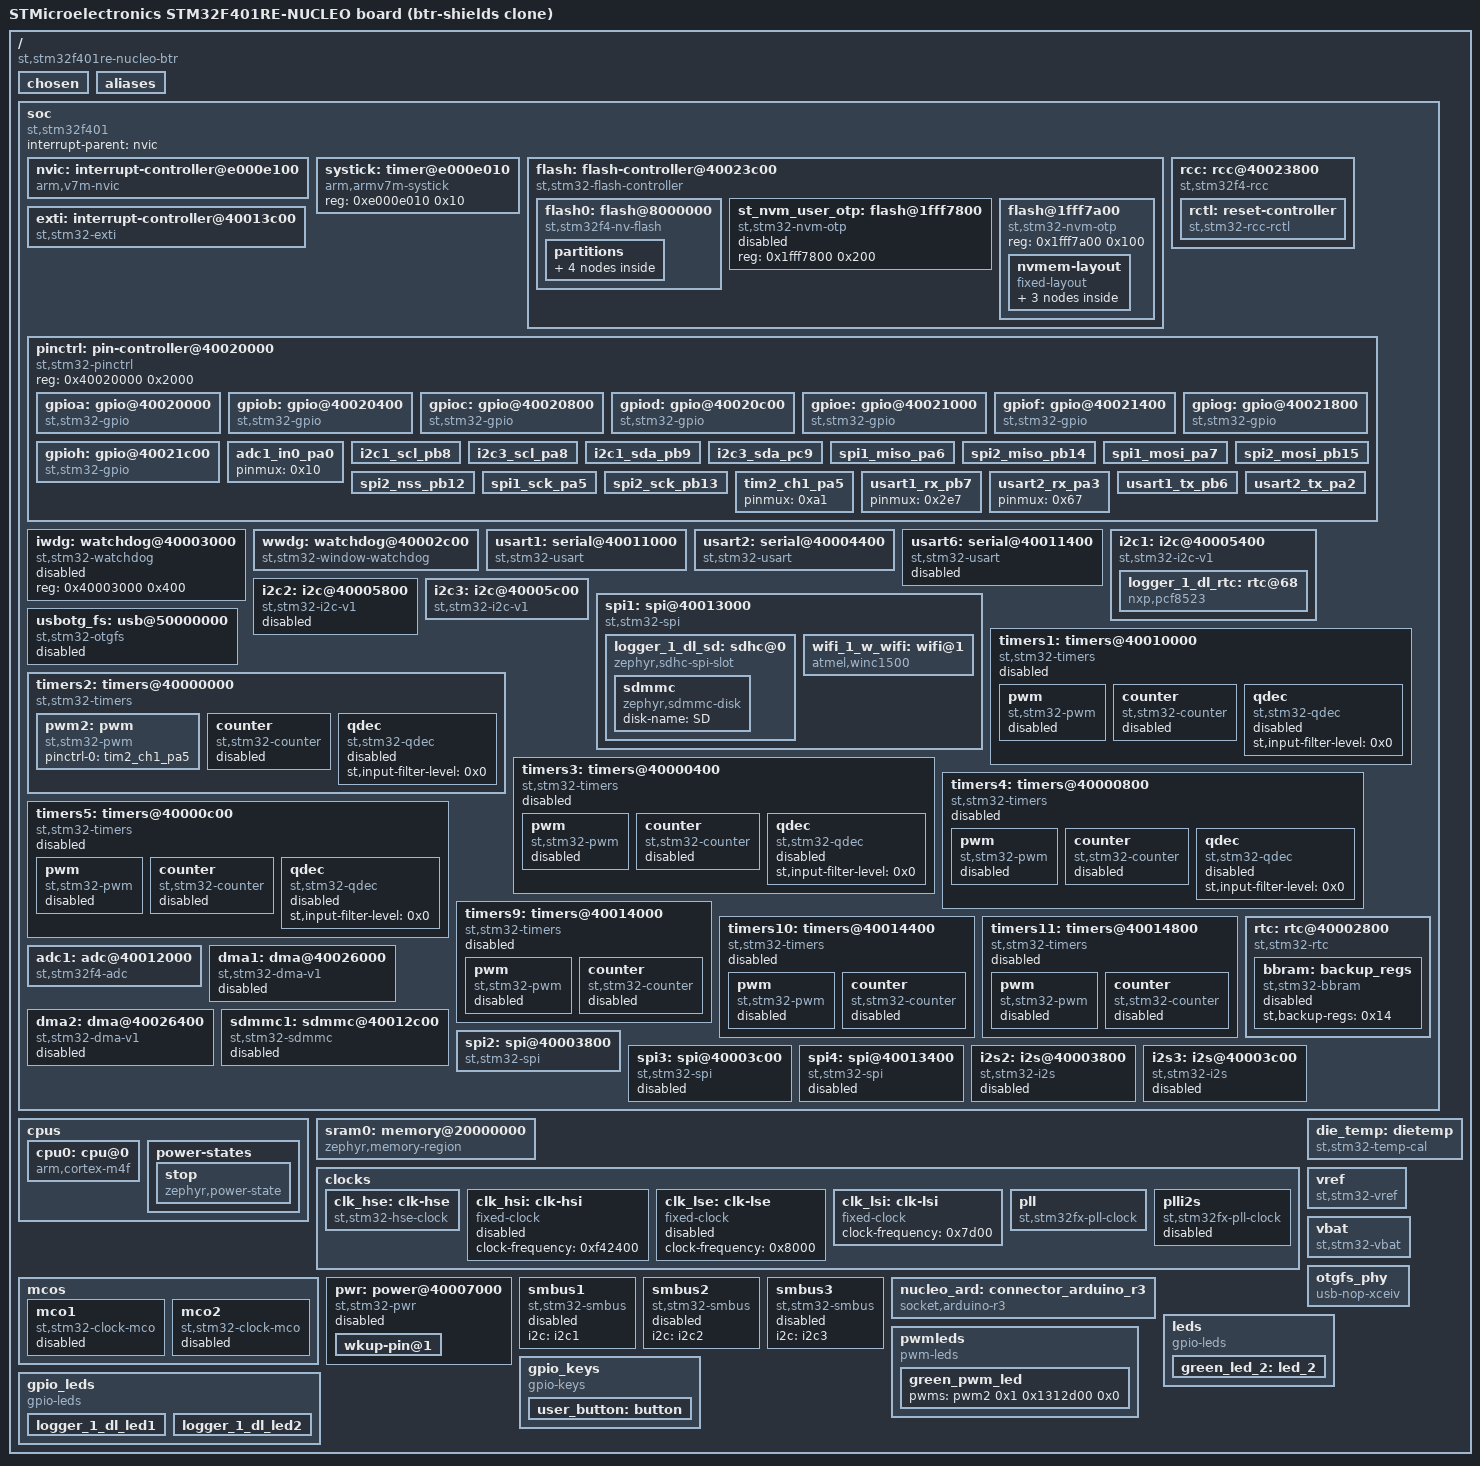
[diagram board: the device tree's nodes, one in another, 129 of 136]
/dts-v1/;

/* node '/' defined in zephyr-rigs/dts/common/skeleton.dtsi:9 */
/ {
	#address-cells = < 0x1 >;                                                  /* in zephyr-rigs/dts/common/skeleton.dtsi:10 */
	#size-cells = < 0x1 >;                                                     /* in zephyr-rigs/dts/common/skeleton.dtsi:11 */
	model = "STMicroelectronics STM32F401RE-NUCLEO board (btr-shields clone)"; /* in btr-shields/boards/st/nucleo_f401re_btr/nucleo_f401re_btr.dts:15 */
	compatible = "st,stm32f401re-nucleo-btr";                                  /* in btr-shields/boards/st/nucleo_f401re_btr/nucleo_f401re_btr.dts:16 */

	/* node '/chosen' defined in zephyr-rigs/dts/common/skeleton.dtsi:13 */
	chosen {
		zephyr,flash-controller = &flash;         /* in zephyr-rigs/dts/arm/st/f4/stm32f4.dtsi:26 */
		zephyr,system-timer-companion = &rtc;     /* in zephyr-rigs/dts/arm/st/f4/stm32f4.dtsi:27 */
		zephyr,console = &usart2;                 /* in btr-shields/boards/st/nucleo_f401re_btr/nucleo_f401re_btr.dts:19 */
		zephyr,shell-uart = &usart2;              /* in btr-shields/boards/st/nucleo_f401re_btr/nucleo_f401re_btr.dts:20 */
		zephyr,sram = &sram0;                     /* in btr-shields/boards/st/nucleo_f401re_btr/nucleo_f401re_btr.dts:21 */
		zephyr,flash = &flash0;                   /* in btr-shields/boards/st/nucleo_f401re_btr/nucleo_f401re_btr.dts:22 */
		zephyr,code-partition = &slot0_partition; /* in btr-shields/boards/st/nucleo_f401re_btr/nucleo_f401re_btr.dts:23 */
	};

	/* node '/aliases' defined in zephyr-rigs/dts/common/skeleton.dtsi:15 */
	aliases {
		led0 = &green_led_2;       /* in btr-shields/boards/st/nucleo_f401re_btr/nucleo_f401re_btr.dts:54 */
		sw0 = &user_button;        /* in btr-shields/boards/st/nucleo_f401re_btr/nucleo_f401re_btr.dts:55 */
		pwm-led0 = &green_pwm_led; /* in btr-shields/boards/st/nucleo_f401re_btr/nucleo_f401re_btr.dts:56 */
		watchdog0 = &wwdg;         /* in btr-shields/boards/st/nucleo_f401re_btr/nucleo_f401re_btr.dts:57 */
		die-temp0 = &die_temp;     /* in btr-shields/boards/st/nucleo_f401re_btr/nucleo_f401re_btr.dts:58 */
		rtc = &rtc;                /* in btr-shields/boards/st/nucleo_f401re_btr/nucleo_f401re_btr.dts:59 */
		volt-sensor0 = &vref;      /* in btr-shields/boards/st/nucleo_f401re_btr/nucleo_f401re_btr.dts:60 */
		volt-sensor1 = &vbat;      /* in btr-shields/boards/st/nucleo_f401re_btr/nucleo_f401re_btr.dts:61 */
	};

	/* node '/soc' defined in zephyr-rigs/dts/arm/armv7-m.dtsi:6 */
	soc {
		#address-cells = < 0x1 >;     /* in zephyr-rigs/dts/arm/armv7-m.dtsi:7 */
		#size-cells = < 0x1 >;        /* in zephyr-rigs/dts/arm/armv7-m.dtsi:8 */
		interrupt-parent = < &nvic >; /* in zephyr-rigs/dts/arm/armv7-m.dtsi:10 */
		ranges;                       /* in zephyr-rigs/dts/arm/armv7-m.dtsi:11 */
		compatible = "st,stm32f401",
		             "st,stm32f4",
		             "simple-bus";    /* in zephyr-rigs/dts/arm/st/f4/stm32f401.dtsi:19 */

		/* node '/soc/interrupt-controller@e000e100' defined in zephyr-rigs/dts/arm/armv7-m.dtsi:13 */
		nvic: interrupt-controller@e000e100 {
			#address-cells = < 0x1 >;            /* in zephyr-rigs/dts/arm/armv7-m.dtsi:14 */
			compatible = "arm,v7m-nvic";         /* in zephyr-rigs/dts/arm/armv7-m.dtsi:15 */
			reg = < 0xe000e100 0xc00 >;          /* in zephyr-rigs/dts/arm/armv7-m.dtsi:16 */
			interrupt-controller;                /* in zephyr-rigs/dts/arm/armv7-m.dtsi:17 */
			#interrupt-cells = < 0x2 >;          /* in zephyr-rigs/dts/arm/armv7-m.dtsi:18 */
			arm,num-irq-priority-bits = < 0x4 >; /* in zephyr-rigs/dts/arm/st/f4/stm32f4.dtsi:729 */
			phandle = < 0x1 >;                   /* in zephyr-rigs/dts/arm/armv7-m.dtsi:10 */
		};

		/* node '/soc/timer@e000e010' defined in zephyr-rigs/dts/arm/armv7-m.dtsi:21 */
		systick: timer@e000e010 {
			compatible = "arm,armv7m-systick"; /* in zephyr-rigs/dts/arm/armv7-m.dtsi:22 */
			reg = < 0xe000e010 0x10 >;         /* in zephyr-rigs/dts/arm/armv7-m.dtsi:23 */
		};

		/* node '/soc/flash-controller@40023c00' defined in zephyr-rigs/dts/arm/st/f4/stm32f4.dtsi:112 */
		flash: flash-controller@40023c00 {
			compatible = "st,stm32-flash-controller",
			             "st,stm32f4-flash-controller"; /* in zephyr-rigs/dts/arm/st/f4/stm32f4.dtsi:113 */
			reg = < 0x40023c00 0x400 >;                 /* in zephyr-rigs/dts/arm/st/f4/stm32f4.dtsi:114 */
			interrupts = < 0x4 0x0 >;                   /* in zephyr-rigs/dts/arm/st/f4/stm32f4.dtsi:115 */
			#address-cells = < 0x1 >;                   /* in zephyr-rigs/dts/arm/st/f4/stm32f4.dtsi:117 */
			#size-cells = < 0x1 >;                      /* in zephyr-rigs/dts/arm/st/f4/stm32f4.dtsi:118 */
			ranges;                                     /* in zephyr-rigs/dts/arm/st/f4/stm32f4.dtsi:119 */

			/* node '/soc/flash-controller@40023c00/flash@8000000' defined in zephyr-rigs/dts/arm/st/f4/stm32f4.dtsi:121 */
			flash0: flash@8000000 {
				compatible = "st,stm32f4-nv-flash",
				             "st,stm32-nv-flash",
				             "soc-nv-flash";        /* in zephyr-rigs/dts/arm/st/f4/stm32f4.dtsi:122 */
				#address-cells = < 0x1 >;           /* in zephyr-rigs/dts/arm/st/f4/stm32f4.dtsi:124 */
				#size-cells = < 0x1 >;              /* in zephyr-rigs/dts/arm/st/f4/stm32f4.dtsi:125 */
				write-block-size = < 0x1 >;         /* in zephyr-rigs/dts/arm/st/f4/stm32f4.dtsi:126 */
				max-erase-time = < 0xfa0 >;         /* in zephyr-rigs/dts/arm/st/f4/stm32f4.dtsi:128 */
				reg = < 0x8000000 0x80000 >;        /* in zephyr-rigs/dts/arm/st/f4/stm32f401Xe.dtsi:17 */
				ranges = < 0x0 0x8000000 0x80000 >; /* in zephyr-rigs/dts/arm/st/f4/stm32f401Xe.dtsi:18 */

				/* node '/soc/flash-controller@40023c00/flash@8000000/partitions' defined in btr-shields/boards/st/nucleo_f401re_btr/nucleo_f401re_btr.dts:139 */
				partitions {
					#address-cells = < 0x1 >; /* in btr-shields/boards/st/nucleo_f401re_btr/nucleo_f401re_btr.dts:140 */
					#size-cells = < 0x1 >;    /* in btr-shields/boards/st/nucleo_f401re_btr/nucleo_f401re_btr.dts:141 */
					ranges;                   /* in btr-shields/boards/st/nucleo_f401re_btr/nucleo_f401re_btr.dts:142 */

					/* node '/soc/flash-controller@40023c00/flash@8000000/partitions/partition@0' defined in btr-shields/boards/st/nucleo_f401re_btr/nucleo_f401re_btr.dts:144 */
					boot_partition: partition@0 {
						compatible = "zephyr,mapped-partition"; /* in btr-shields/boards/st/nucleo_f401re_btr/nucleo_f401re_btr.dts:145 */
						label = "mcuboot";                      /* in btr-shields/boards/st/nucleo_f401re_btr/nucleo_f401re_btr.dts:146 */
						reg = < 0x0 0x10000 >;                  /* in btr-shields/boards/st/nucleo_f401re_btr/nucleo_f401re_btr.dts:147 */
						read-only;                              /* in btr-shields/boards/st/nucleo_f401re_btr/nucleo_f401re_btr.dts:148 */
					};

					/* node '/soc/flash-controller@40023c00/flash@8000000/partitions/partition@20000' defined in btr-shields/boards/st/nucleo_f401re_btr/nucleo_f401re_btr.dts:156 */
					slot0_partition: partition@20000 {
						compatible = "zephyr,mapped-partition"; /* in btr-shields/boards/st/nucleo_f401re_btr/nucleo_f401re_btr.dts:157 */
						label = "image-0";                      /* in btr-shields/boards/st/nucleo_f401re_btr/nucleo_f401re_btr.dts:158 */
						reg = < 0x20000 0x20000 >;              /* in btr-shields/boards/st/nucleo_f401re_btr/nucleo_f401re_btr.dts:159 */
					};

					/* node '/soc/flash-controller@40023c00/flash@8000000/partitions/partition@40000' defined in btr-shields/boards/st/nucleo_f401re_btr/nucleo_f401re_btr.dts:162 */
					slot1_partition: partition@40000 {
						compatible = "zephyr,mapped-partition"; /* in btr-shields/boards/st/nucleo_f401re_btr/nucleo_f401re_btr.dts:163 */
						label = "image-1";                      /* in btr-shields/boards/st/nucleo_f401re_btr/nucleo_f401re_btr.dts:164 */
						reg = < 0x40000 0x20000 >;              /* in btr-shields/boards/st/nucleo_f401re_btr/nucleo_f401re_btr.dts:165 */
					};

					/* node '/soc/flash-controller@40023c00/flash@8000000/partitions/partition@60000' defined in btr-shields/boards/st/nucleo_f401re_btr/nucleo_f401re_btr.dts:168 */
					scratch_partition: partition@60000 {
						compatible = "zephyr,mapped-partition"; /* in btr-shields/boards/st/nucleo_f401re_btr/nucleo_f401re_btr.dts:169 */
						label = "image-scratch";                /* in btr-shields/boards/st/nucleo_f401re_btr/nucleo_f401re_btr.dts:170 */
						reg = < 0x60000 0x20000 >;              /* in btr-shields/boards/st/nucleo_f401re_btr/nucleo_f401re_btr.dts:171 */
					};
				};
			};

			/* node '/soc/flash-controller@40023c00/flash@1fff7800' defined in zephyr-rigs/dts/arm/st/f4/stm32f4.dtsi:131 */
			st_nvm_user_otp: flash@1fff7800 {
				compatible = "st,stm32-nvm-otp"; /* in zephyr-rigs/dts/arm/st/f4/stm32f4.dtsi:132 */
				reg = < 0x1fff7800 0x200 >;      /* in zephyr-rigs/dts/arm/st/f4/stm32f4.dtsi:133 */
				status = "disabled";             /* in zephyr-rigs/dts/arm/st/f4/stm32f4.dtsi:134 */
			};

			/* node '/soc/flash-controller@40023c00/flash@1fff7a00' defined in zephyr-rigs/dts/arm/st/f4/stm32f4.dtsi:148 */
			flash@1fff7a00 {
				compatible = "st,stm32-nvm-otp"; /* in zephyr-rigs/dts/arm/st/f4/stm32f4.dtsi:149 */
				reg = < 0x1fff7a00 0x100 >;      /* in zephyr-rigs/dts/arm/st/f4/stm32f4.dtsi:150 */

				/* node '/soc/flash-controller@40023c00/flash@1fff7a00/nvmem-layout' defined in zephyr-rigs/dts/arm/st/f4/stm32f4.dtsi:152 */
				nvmem-layout {
					compatible = "fixed-layout"; /* in zephyr-rigs/dts/arm/st/f4/stm32f4.dtsi:153 */
					#address-cells = < 0x1 >;    /* in zephyr-rigs/dts/arm/st/f4/stm32f4.dtsi:154 */
					#size-cells = < 0x1 >;       /* in zephyr-rigs/dts/arm/st/f4/stm32f4.dtsi:155 */

					/* node '/soc/flash-controller@40023c00/flash@1fff7a00/nvmem-layout/vrefint@2a' defined in zephyr-rigs/dts/arm/st/f4/stm32f4.dtsi:157 */
					vrefint_otp: vrefint@2a {
						reg = < 0x2a 0x2 >;          /* in zephyr-rigs/dts/arm/st/f4/stm32f4.dtsi:158 */
						#nvmem-cell-cells = < 0x0 >; /* in zephyr-rigs/dts/arm/st/f4/stm32f4.dtsi:159 */
						read-only;                   /* in zephyr-rigs/dts/arm/st/f4/stm32f4.dtsi:160 */
						phandle = < 0x21 >;          /* in zephyr-rigs/dts/arm/st/f4/stm32f4.dtsi:685 */
					};

					/* node '/soc/flash-controller@40023c00/flash@1fff7a00/nvmem-layout/ts-cal1@2c' defined in zephyr-rigs/dts/arm/st/f4/stm32f4.dtsi:163 */
					ts_cal1_otp: ts-cal1@2c {
						reg = < 0x2c 0x2 >;          /* in zephyr-rigs/dts/arm/st/f4/stm32f4.dtsi:164 */
						#nvmem-cell-cells = < 0x0 >; /* in zephyr-rigs/dts/arm/st/f4/stm32f4.dtsi:165 */
						read-only;                   /* in zephyr-rigs/dts/arm/st/f4/stm32f4.dtsi:166 */
						phandle = < 0x1e >;          /* in zephyr-rigs/dts/arm/st/f4/stm32f4.dtsi:674 */
					};

					/* node '/soc/flash-controller@40023c00/flash@1fff7a00/nvmem-layout/ts-cal2@2e' defined in zephyr-rigs/dts/arm/st/f4/stm32f4.dtsi:169 */
					ts_cal2_otp: ts-cal2@2e {
						reg = < 0x2e 0x2 >;          /* in zephyr-rigs/dts/arm/st/f4/stm32f4.dtsi:170 */
						#nvmem-cell-cells = < 0x0 >; /* in zephyr-rigs/dts/arm/st/f4/stm32f4.dtsi:171 */
						read-only;                   /* in zephyr-rigs/dts/arm/st/f4/stm32f4.dtsi:172 */
						phandle = < 0x1f >;          /* in zephyr-rigs/dts/arm/st/f4/stm32f4.dtsi:674 */
					};
				};
			};
		};

		/* node '/soc/rcc@40023800' defined in zephyr-rigs/dts/arm/st/f4/stm32f4.dtsi:178 */
		rcc: rcc@40023800 {
			compatible = "st,stm32f4-rcc";   /* in zephyr-rigs/dts/arm/st/f4/stm32f4.dtsi:179 */
			#clock-cells = < 0x2 >;          /* in zephyr-rigs/dts/arm/st/f4/stm32f4.dtsi:180 */
			reg = < 0x40023800 0x400 >;      /* in zephyr-rigs/dts/arm/st/f4/stm32f4.dtsi:181 */
			clocks = < &pll >;               /* in btr-shields/boards/st/nucleo_f401re_btr/nucleo_f401re_btr.dts:85 */
			clock-frequency = < 0x501bd00 >; /* in btr-shields/boards/st/nucleo_f401re_btr/nucleo_f401re_btr.dts:86 */
			ahb-prescaler = < 0x1 >;         /* in btr-shields/boards/st/nucleo_f401re_btr/nucleo_f401re_btr.dts:87 */
			apb1-prescaler = < 0x2 >;        /* in btr-shields/boards/st/nucleo_f401re_btr/nucleo_f401re_btr.dts:88 */
			apb2-prescaler = < 0x1 >;        /* in btr-shields/boards/st/nucleo_f401re_btr/nucleo_f401re_btr.dts:89 */
			phandle = < 0x3 >;               /* in zephyr-rigs/dts/arm/st/f4/stm32f4.dtsi:195 */

			/* node '/soc/rcc@40023800/reset-controller' defined in zephyr-rigs/dts/arm/st/f4/stm32f4.dtsi:183 */
			rctl: reset-controller {
				compatible = "st,stm32-rcc-rctl"; /* in zephyr-rigs/dts/arm/st/f4/stm32f4.dtsi:184 */
				#reset-cells = < 0x1 >;           /* in zephyr-rigs/dts/arm/st/f4/stm32f4.dtsi:185 */
				phandle = < 0x4 >;                /* in zephyr-rigs/dts/arm/st/f4/stm32f4.dtsi:294 */
			};
		};

		/* node '/soc/interrupt-controller@40013c00' defined in zephyr-rigs/dts/arm/st/f4/stm32f4.dtsi:189 */
		exti: interrupt-controller@40013c00 {
			compatible = "st,stm32-exti";  /* in zephyr-rigs/dts/arm/st/f4/stm32f4.dtsi:190 */
			interrupt-controller;          /* in zephyr-rigs/dts/arm/st/f4/stm32f4.dtsi:191 */
			#interrupt-cells = < 0x1 >;    /* in zephyr-rigs/dts/arm/st/f4/stm32f4.dtsi:192 */
			#address-cells = < 0x0 >;      /* in zephyr-rigs/dts/arm/st/f4/stm32f4.dtsi:193 */
			reg = < 0x40013c00 0x400 >;    /* in zephyr-rigs/dts/arm/st/f4/stm32f4.dtsi:194 */
			clocks = < &rcc 0x44 0x4000 >; /* in zephyr-rigs/dts/arm/st/f4/stm32f4.dtsi:195 */
			num-lines = < 0x20 >;          /* in zephyr-rigs/dts/arm/st/f4/stm32f4.dtsi:196 */
			interrupts = < 0x6 0x0 >,
			             < 0x7 0x0 >,
			             < 0x8 0x0 >,
			             < 0x9 0x0 >,
			             < 0xa 0x0 >,
			             < 0x17 0x0 >,
			             < 0x28 0x0 >;     /* in zephyr-rigs/dts/arm/st/f4/stm32f4.dtsi:197 */
			interrupt-names = "line0",
			                  "line1",
			                  "line2",
			                  "line3",
			                  "line4",
			                  "line5-9",
			                  "line10-15"; /* in zephyr-rigs/dts/arm/st/f4/stm32f4.dtsi:199 */
			line-ranges = < 0x0 0x1 >,
			              < 0x1 0x1 >,
			              < 0x2 0x1 >,
			              < 0x3 0x1 >,
			              < 0x4 0x1 >,
			              < 0x5 0x5 >,
			              < 0xa 0x6 >;     /* in zephyr-rigs/dts/arm/st/f4/stm32f4.dtsi:201 */
		};

		/* node '/soc/pin-controller@40020000' defined in zephyr-rigs/dts/arm/st/f4/stm32f4.dtsi:205 */
		pinctrl: pin-controller@40020000 {
			compatible = "st,stm32-pinctrl"; /* in zephyr-rigs/dts/arm/st/f4/stm32f4.dtsi:206 */
			#address-cells = < 0x1 >;        /* in zephyr-rigs/dts/arm/st/f4/stm32f4.dtsi:207 */
			#size-cells = < 0x1 >;           /* in zephyr-rigs/dts/arm/st/f4/stm32f4.dtsi:208 */
			reg = < 0x40020000 0x2000 >;     /* in zephyr-rigs/dts/arm/st/f4/stm32f4.dtsi:209 */

			/* node '/soc/pin-controller@40020000/gpio@40020000' defined in zephyr-rigs/dts/arm/st/f4/stm32f4.dtsi:211 */
			gpioa: gpio@40020000 {
				compatible = "st,stm32-gpio"; /* in zephyr-rigs/dts/arm/st/f4/stm32f4.dtsi:212 */
				gpio-controller;              /* in zephyr-rigs/dts/arm/st/f4/stm32f4.dtsi:213 */
				#gpio-cells = < 0x2 >;        /* in zephyr-rigs/dts/arm/st/f4/stm32f4.dtsi:214 */
				reg = < 0x40020000 0x400 >;   /* in zephyr-rigs/dts/arm/st/f4/stm32f4.dtsi:215 */
				clocks = < &rcc 0x30 0x1 >;   /* in zephyr-rigs/dts/arm/st/f4/stm32f4.dtsi:216 */
				phandle = < 0xf >;            /* in btr-shields/boards/st/nucleo_f401re_btr/nucleo_f401re_btr.dts:118 */
			};

			/* node '/soc/pin-controller@40020000/gpio@40020400' defined in zephyr-rigs/dts/arm/st/f4/stm32f4.dtsi:219 */
			gpiob: gpio@40020400 {
				compatible = "st,stm32-gpio"; /* in zephyr-rigs/dts/arm/st/f4/stm32f4.dtsi:220 */
				gpio-controller;              /* in zephyr-rigs/dts/arm/st/f4/stm32f4.dtsi:221 */
				#gpio-cells = < 0x2 >;        /* in zephyr-rigs/dts/arm/st/f4/stm32f4.dtsi:222 */
				reg = < 0x40020400 0x400 >;   /* in zephyr-rigs/dts/arm/st/f4/stm32f4.dtsi:223 */
				clocks = < &rcc 0x30 0x2 >;   /* in zephyr-rigs/dts/arm/st/f4/stm32f4.dtsi:224 */
				phandle = < 0xb >;            /* in btr-shields/boards/st/nucleo_f401re_btr/nucleo_f401re_btr.dts:109 */
			};

			/* node '/soc/pin-controller@40020000/gpio@40020800' defined in zephyr-rigs/dts/arm/st/f4/stm32f4.dtsi:227 */
			gpioc: gpio@40020800 {
				compatible = "st,stm32-gpio"; /* in zephyr-rigs/dts/arm/st/f4/stm32f4.dtsi:228 */
				gpio-controller;              /* in zephyr-rigs/dts/arm/st/f4/stm32f4.dtsi:229 */
				#gpio-cells = < 0x2 >;        /* in zephyr-rigs/dts/arm/st/f4/stm32f4.dtsi:230 */
				reg = < 0x40020800 0x400 >;   /* in zephyr-rigs/dts/arm/st/f4/stm32f4.dtsi:231 */
				clocks = < &rcc 0x30 0x4 >;   /* in zephyr-rigs/dts/arm/st/f4/stm32f4.dtsi:232 */
				phandle = < 0x10 >;           /* in btr-shields/boards/st/nucleo_f401re_btr/nucleo_f401re_btr.dts:119 */
			};

			/* node '/soc/pin-controller@40020000/gpio@40020c00' defined in zephyr-rigs/dts/arm/st/f4/stm32f4.dtsi:235 */
			gpiod: gpio@40020c00 {
				compatible = "st,stm32-gpio"; /* in zephyr-rigs/dts/arm/st/f4/stm32f4.dtsi:236 */
				gpio-controller;              /* in zephyr-rigs/dts/arm/st/f4/stm32f4.dtsi:237 */
				#gpio-cells = < 0x2 >;        /* in zephyr-rigs/dts/arm/st/f4/stm32f4.dtsi:238 */
				reg = < 0x40020c00 0x400 >;   /* in zephyr-rigs/dts/arm/st/f4/stm32f4.dtsi:239 */
				clocks = < &rcc 0x30 0x8 >;   /* in zephyr-rigs/dts/arm/st/f4/stm32f4.dtsi:240 */
			};

			/* node '/soc/pin-controller@40020000/gpio@40021000' defined in zephyr-rigs/dts/arm/st/f4/stm32f4.dtsi:243 */
			gpioe: gpio@40021000 {
				compatible = "st,stm32-gpio"; /* in zephyr-rigs/dts/arm/st/f4/stm32f4.dtsi:244 */
				gpio-controller;              /* in zephyr-rigs/dts/arm/st/f4/stm32f4.dtsi:245 */
				#gpio-cells = < 0x2 >;        /* in zephyr-rigs/dts/arm/st/f4/stm32f4.dtsi:246 */
				reg = < 0x40021000 0x400 >;   /* in zephyr-rigs/dts/arm/st/f4/stm32f4.dtsi:247 */
				clocks = < &rcc 0x30 0x10 >;  /* in zephyr-rigs/dts/arm/st/f4/stm32f4.dtsi:248 */
			};

			/* node '/soc/pin-controller@40020000/gpio@40021400' defined in zephyr-rigs/dts/arm/st/f4/stm32f4.dtsi:251 */
			gpiof: gpio@40021400 {
				compatible = "st,stm32-gpio"; /* in zephyr-rigs/dts/arm/st/f4/stm32f4.dtsi:252 */
				gpio-controller;              /* in zephyr-rigs/dts/arm/st/f4/stm32f4.dtsi:253 */
				#gpio-cells = < 0x2 >;        /* in zephyr-rigs/dts/arm/st/f4/stm32f4.dtsi:254 */
				reg = < 0x40021400 0x400 >;   /* in zephyr-rigs/dts/arm/st/f4/stm32f4.dtsi:255 */
				clocks = < &rcc 0x30 0x20 >;  /* in zephyr-rigs/dts/arm/st/f4/stm32f4.dtsi:256 */
			};

			/* node '/soc/pin-controller@40020000/gpio@40021800' defined in zephyr-rigs/dts/arm/st/f4/stm32f4.dtsi:259 */
			gpiog: gpio@40021800 {
				compatible = "st,stm32-gpio"; /* in zephyr-rigs/dts/arm/st/f4/stm32f4.dtsi:260 */
				gpio-controller;              /* in zephyr-rigs/dts/arm/st/f4/stm32f4.dtsi:261 */
				#gpio-cells = < 0x2 >;        /* in zephyr-rigs/dts/arm/st/f4/stm32f4.dtsi:262 */
				reg = < 0x40021800 0x400 >;   /* in zephyr-rigs/dts/arm/st/f4/stm32f4.dtsi:263 */
				clocks = < &rcc 0x30 0x40 >;  /* in zephyr-rigs/dts/arm/st/f4/stm32f4.dtsi:264 */
			};

			/* node '/soc/pin-controller@40020000/gpio@40021c00' defined in zephyr-rigs/dts/arm/st/f4/stm32f4.dtsi:267 */
			gpioh: gpio@40021c00 {
				compatible = "st,stm32-gpio"; /* in zephyr-rigs/dts/arm/st/f4/stm32f4.dtsi:268 */
				gpio-controller;              /* in zephyr-rigs/dts/arm/st/f4/stm32f4.dtsi:269 */
				#gpio-cells = < 0x2 >;        /* in zephyr-rigs/dts/arm/st/f4/stm32f4.dtsi:270 */
				reg = < 0x40021c00 0x400 >;   /* in zephyr-rigs/dts/arm/st/f4/stm32f4.dtsi:271 */
				clocks = < &rcc 0x30 0x80 >;  /* in zephyr-rigs/dts/arm/st/f4/stm32f4.dtsi:272 */
			};

			/* node '/soc/pin-controller@40020000/adc1_in0_pa0' defined in modules/hal/stm32/dts/st/f4/stm32f401r(d-e)tx-pinctrl.dtsi:13 */
			adc1_in0_pa0: adc1_in0_pa0 {
				pinmux = < 0x10 >;  /* in modules/hal/stm32/dts/st/f4/stm32f401r(d-e)tx-pinctrl.dtsi:14 */
				phandle = < 0x16 >; /* in btr-shields/boards/st/nucleo_f401re_btr/nucleo_f401re_btr.dts:193 */
			};

			/* node '/soc/pin-controller@40020000/i2c1_scl_pb8' defined in modules/hal/stm32/dts/st/f4/stm32f401r(d-e)tx-pinctrl.dtsi:287 */
			i2c1_scl_pb8: i2c1_scl_pb8 {
				pinmux = < 0x304 >; /* in modules/hal/stm32/dts/st/f4/stm32f401r(d-e)tx-pinctrl.dtsi:288 */
				bias-pull-up;       /* in modules/hal/stm32/dts/st/f4/stm32f401r(d-e)tx-pinctrl.dtsi:289 */
				drive-open-drain;   /* in modules/hal/stm32/dts/st/f4/stm32f401r(d-e)tx-pinctrl.dtsi:290 */
				phandle = < 0x9 >;  /* in btr-shields/boards/st/nucleo_f401re_btr/nucleo_f401re_btr.dts:107 */
			};

			/* node '/soc/pin-controller@40020000/i2c3_scl_pa8' defined in modules/hal/stm32/dts/st/f4/stm32f401r(d-e)tx-pinctrl.dtsi:299 */
			i2c3_scl_pa8: i2c3_scl_pa8 {
				pinmux = < 0x104 >; /* in modules/hal/stm32/dts/st/f4/stm32f401r(d-e)tx-pinctrl.dtsi:300 */
				bias-pull-up;       /* in modules/hal/stm32/dts/st/f4/stm32f401r(d-e)tx-pinctrl.dtsi:301 */
				drive-open-drain;   /* in modules/hal/stm32/dts/st/f4/stm32f401r(d-e)tx-pinctrl.dtsi:302 */
				phandle = < 0xd >;  /* in btr-shields/boards/st/nucleo_f401re_btr/nucleo_f401re_btr.dts:116 */
			};

			/* node '/soc/pin-controller@40020000/i2c1_sda_pb9' defined in modules/hal/stm32/dts/st/f4/stm32f401r(d-e)tx-pinctrl.dtsi:313 */
			i2c1_sda_pb9: i2c1_sda_pb9 {
				pinmux = < 0x324 >; /* in modules/hal/stm32/dts/st/f4/stm32f401r(d-e)tx-pinctrl.dtsi:314 */
				bias-pull-up;       /* in modules/hal/stm32/dts/st/f4/stm32f401r(d-e)tx-pinctrl.dtsi:315 */
				drive-open-drain;   /* in modules/hal/stm32/dts/st/f4/stm32f401r(d-e)tx-pinctrl.dtsi:316 */
				phandle = < 0xa >;  /* in btr-shields/boards/st/nucleo_f401re_btr/nucleo_f401re_btr.dts:107 */
			};

			/* node '/soc/pin-controller@40020000/i2c3_sda_pc9' defined in modules/hal/stm32/dts/st/f4/stm32f401r(d-e)tx-pinctrl.dtsi:331 */
			i2c3_sda_pc9: i2c3_sda_pc9 {
				pinmux = < 0x524 >; /* in modules/hal/stm32/dts/st/f4/stm32f401r(d-e)tx-pinctrl.dtsi:332 */
				bias-pull-up;       /* in modules/hal/stm32/dts/st/f4/stm32f401r(d-e)tx-pinctrl.dtsi:333 */
				drive-open-drain;   /* in modules/hal/stm32/dts/st/f4/stm32f401r(d-e)tx-pinctrl.dtsi:334 */
				phandle = < 0xe >;  /* in btr-shields/boards/st/nucleo_f401re_btr/nucleo_f401re_btr.dts:116 */
			};

			/* node '/soc/pin-controller@40020000/spi1_miso_pa6' defined in modules/hal/stm32/dts/st/f4/stm32f401r(d-e)tx-pinctrl.dtsi:522 */
			spi1_miso_pa6: spi1_miso_pa6 {
				pinmux = < 0xc5 >;             /* in modules/hal/stm32/dts/st/f4/stm32f401r(d-e)tx-pinctrl.dtsi:523 */
				bias-pull-down;                /* in modules/hal/stm32/dts/st/f4/stm32f401r(d-e)tx-pinctrl.dtsi:524 */
				slew-rate = "very-high-speed"; /* in modules/hal/stm32/dts/st/f4/stm32f401r(d-e)tx-pinctrl.dtsi:525 */
				phandle = < 0x12 >;            /* in btr-shields/boards/st/nucleo_f401re_btr/nucleo_f401re_btr.dts:125 */
			};

			/* node '/soc/pin-controller@40020000/spi2_miso_pb14' defined in modules/hal/stm32/dts/st/f4/stm32f401r(d-e)tx-pinctrl.dtsi:534 */
			spi2_miso_pb14: spi2_miso_pb14 {
				pinmux = < 0x3c5 >;            /* in modules/hal/stm32/dts/st/f4/stm32f401r(d-e)tx-pinctrl.dtsi:535 */
				bias-pull-down;                /* in modules/hal/stm32/dts/st/f4/stm32f401r(d-e)tx-pinctrl.dtsi:536 */
				slew-rate = "very-high-speed"; /* in modules/hal/stm32/dts/st/f4/stm32f401r(d-e)tx-pinctrl.dtsi:537 */
				phandle = < 0x19 >;            /* in btr-shields/boards/st/nucleo_f401re_btr/nucleo_f401re_btr.dts:132 */
			};

			/* node '/soc/pin-controller@40020000/spi1_mosi_pa7' defined in modules/hal/stm32/dts/st/f4/stm32f401r(d-e)tx-pinctrl.dtsi:560 */
			spi1_mosi_pa7: spi1_mosi_pa7 {
				pinmux = < 0xe5 >;             /* in modules/hal/stm32/dts/st/f4/stm32f401r(d-e)tx-pinctrl.dtsi:561 */
				bias-pull-down;                /* in modules/hal/stm32/dts/st/f4/stm32f401r(d-e)tx-pinctrl.dtsi:562 */
				slew-rate = "very-high-speed"; /* in modules/hal/stm32/dts/st/f4/stm32f401r(d-e)tx-pinctrl.dtsi:563 */
				phandle = < 0x13 >;            /* in btr-shields/boards/st/nucleo_f401re_btr/nucleo_f401re_btr.dts:125 */
			};

			/* node '/soc/pin-controller@40020000/spi2_mosi_pb15' defined in modules/hal/stm32/dts/st/f4/stm32f401r(d-e)tx-pinctrl.dtsi:572 */
			spi2_mosi_pb15: spi2_mosi_pb15 {
				pinmux = < 0x3e5 >;            /* in modules/hal/stm32/dts/st/f4/stm32f401r(d-e)tx-pinctrl.dtsi:573 */
				bias-pull-down;                /* in modules/hal/stm32/dts/st/f4/stm32f401r(d-e)tx-pinctrl.dtsi:574 */
				slew-rate = "very-high-speed"; /* in modules/hal/stm32/dts/st/f4/stm32f401r(d-e)tx-pinctrl.dtsi:575 */
				phandle = < 0x1a >;            /* in btr-shields/boards/st/nucleo_f401re_btr/nucleo_f401re_btr.dts:132 */
			};

			/* node '/soc/pin-controller@40020000/spi2_nss_pb12' defined in modules/hal/stm32/dts/st/f4/stm32f401r(d-e)tx-pinctrl.dtsi:616 */
			spi2_nss_pb12: spi2_nss_pb12 {
				pinmux = < 0x385 >;            /* in modules/hal/stm32/dts/st/f4/stm32f401r(d-e)tx-pinctrl.dtsi:617 */
				bias-pull-up;                  /* in modules/hal/stm32/dts/st/f4/stm32f401r(d-e)tx-pinctrl.dtsi:618 */
				slew-rate = "very-high-speed"; /* in modules/hal/stm32/dts/st/f4/stm32f401r(d-e)tx-pinctrl.dtsi:619 */
				phandle = < 0x17 >;            /* in btr-shields/boards/st/nucleo_f401re_btr/nucleo_f401re_btr.dts:132 */
			};

			/* node '/soc/pin-controller@40020000/spi1_sck_pa5' defined in modules/hal/stm32/dts/st/f4/stm32f401r(d-e)tx-pinctrl.dtsi:636 */
			spi1_sck_pa5: spi1_sck_pa5 {
				pinmux = < 0xa5 >;             /* in modules/hal/stm32/dts/st/f4/stm32f401r(d-e)tx-pinctrl.dtsi:637 */
				bias-pull-down;                /* in modules/hal/stm32/dts/st/f4/stm32f401r(d-e)tx-pinctrl.dtsi:638 */
				slew-rate = "very-high-speed"; /* in modules/hal/stm32/dts/st/f4/stm32f401r(d-e)tx-pinctrl.dtsi:639 */
				phandle = < 0x11 >;            /* in btr-shields/boards/st/nucleo_f401re_btr/nucleo_f401re_btr.dts:125 */
			};

			/* node '/soc/pin-controller@40020000/spi2_sck_pb13' defined in modules/hal/stm32/dts/st/f4/stm32f401r(d-e)tx-pinctrl.dtsi:654 */
			spi2_sck_pb13: spi2_sck_pb13 {
				pinmux = < 0x3a5 >;            /* in modules/hal/stm32/dts/st/f4/stm32f401r(d-e)tx-pinctrl.dtsi:655 */
				bias-pull-down;                /* in modules/hal/stm32/dts/st/f4/stm32f401r(d-e)tx-pinctrl.dtsi:656 */
				slew-rate = "very-high-speed"; /* in modules/hal/stm32/dts/st/f4/stm32f401r(d-e)tx-pinctrl.dtsi:657 */
				phandle = < 0x18 >;            /* in btr-shields/boards/st/nucleo_f401re_btr/nucleo_f401re_btr.dts:132 */
			};

			/* node '/soc/pin-controller@40020000/tim2_ch1_pa5' defined in modules/hal/stm32/dts/st/f4/stm32f401r(d-e)tx-pinctrl.dtsi:748 */
			tim2_ch1_pa5: tim2_ch1_pa5 {
				pinmux = < 0xa1 >;  /* in modules/hal/stm32/dts/st/f4/stm32f401r(d-e)tx-pinctrl.dtsi:749 */
				phandle = < 0x15 >; /* in btr-shields/boards/st/nucleo_f401re_btr/nucleo_f401re_btr.dts:181 */
			};

			/* node '/soc/pin-controller@40020000/usart1_rx_pb7' defined in modules/hal/stm32/dts/st/f4/stm32f401r(d-e)tx-pinctrl.dtsi:874 */
			usart1_rx_pb7: usart1_rx_pb7 {
				pinmux = < 0x2e7 >; /* in modules/hal/stm32/dts/st/f4/stm32f401r(d-e)tx-pinctrl.dtsi:875 */
				phandle = < 0x6 >;  /* in btr-shields/boards/st/nucleo_f401re_btr/nucleo_f401re_btr.dts:93 */
			};

			/* node '/soc/pin-controller@40020000/usart2_rx_pa3' defined in modules/hal/stm32/dts/st/f4/stm32f401r(d-e)tx-pinctrl.dtsi:878 */
			usart2_rx_pa3: usart2_rx_pa3 {
				pinmux = < 0x67 >; /* in modules/hal/stm32/dts/st/f4/stm32f401r(d-e)tx-pinctrl.dtsi:879 */
				phandle = < 0x8 >; /* in btr-shields/boards/st/nucleo_f401re_btr/nucleo_f401re_btr.dts:100 */
			};

			/* node '/soc/pin-controller@40020000/usart1_tx_pb6' defined in modules/hal/stm32/dts/st/f4/stm32f401r(d-e)tx-pinctrl.dtsi:897 */
			usart1_tx_pb6: usart1_tx_pb6 {
				pinmux = < 0x2c7 >; /* in modules/hal/stm32/dts/st/f4/stm32f401r(d-e)tx-pinctrl.dtsi:898 */
				bias-pull-up;       /* in modules/hal/stm32/dts/st/f4/stm32f401r(d-e)tx-pinctrl.dtsi:899 */
				phandle = < 0x5 >;  /* in btr-shields/boards/st/nucleo_f401re_btr/nucleo_f401re_btr.dts:93 */
			};

			/* node '/soc/pin-controller@40020000/usart2_tx_pa2' defined in modules/hal/stm32/dts/st/f4/stm32f401r(d-e)tx-pinctrl.dtsi:902 */
			usart2_tx_pa2: usart2_tx_pa2 {
				pinmux = < 0x47 >; /* in modules/hal/stm32/dts/st/f4/stm32f401r(d-e)tx-pinctrl.dtsi:903 */
				bias-pull-up;      /* in modules/hal/stm32/dts/st/f4/stm32f401r(d-e)tx-pinctrl.dtsi:904 */
				phandle = < 0x7 >; /* in btr-shields/boards/st/nucleo_f401re_btr/nucleo_f401re_btr.dts:100 */
			};
		};

		/* node '/soc/watchdog@40003000' defined in zephyr-rigs/dts/arm/st/f4/stm32f4.dtsi:276 */
		iwdg: watchdog@40003000 {
			compatible = "st,stm32-watchdog"; /* in zephyr-rigs/dts/arm/st/f4/stm32f4.dtsi:277 */
			reg = < 0x40003000 0x400 >;       /* in zephyr-rigs/dts/arm/st/f4/stm32f4.dtsi:278 */
			status = "disabled";              /* in zephyr-rigs/dts/arm/st/f4/stm32f4.dtsi:279 */
		};

		/* node '/soc/watchdog@40002c00' defined in zephyr-rigs/dts/arm/st/f4/stm32f4.dtsi:282 */
		wwdg: watchdog@40002c00 {
			compatible = "st,stm32-window-watchdog"; /* in zephyr-rigs/dts/arm/st/f4/stm32f4.dtsi:283 */
			reg = < 0x40002c00 0x400 >;              /* in zephyr-rigs/dts/arm/st/f4/stm32f4.dtsi:284 */
			clocks = < &rcc 0x40 0x800 >;            /* in zephyr-rigs/dts/arm/st/f4/stm32f4.dtsi:285 */
			interrupts = < 0x0 0x0 >;                /* in zephyr-rigs/dts/arm/st/f4/stm32f4.dtsi:286 */
			status = "okay";                         /* in btr-shields/boards/st/nucleo_f401re_btr/nucleo_f401re_btr.dts:205 */
		};

		/* node '/soc/serial@40011000' defined in zephyr-rigs/dts/arm/st/f4/stm32f4.dtsi:290 */
		usart1: serial@40011000 {
			compatible = "st,stm32-usart",
			             "st,stm32-uart";                  /* in zephyr-rigs/dts/arm/st/f4/stm32f4.dtsi:291 */
			reg = < 0x40011000 0x400 >;                    /* in zephyr-rigs/dts/arm/st/f4/stm32f4.dtsi:292 */
			clocks = < &rcc 0x44 0x10 >;                   /* in zephyr-rigs/dts/arm/st/f4/stm32f4.dtsi:293 */
			resets = < &rctl 0x484 >;                      /* in zephyr-rigs/dts/arm/st/f4/stm32f4.dtsi:294 */
			interrupts = < 0x25 0x0 >;                     /* in zephyr-rigs/dts/arm/st/f4/stm32f4.dtsi:295 */
			pinctrl-0 = < &usart1_tx_pb6 &usart1_rx_pb7 >; /* in btr-shields/boards/st/nucleo_f401re_btr/nucleo_f401re_btr.dts:93 */
			pinctrl-names = "default";                     /* in btr-shields/boards/st/nucleo_f401re_btr/nucleo_f401re_btr.dts:94 */
			current-speed = < 0x1c200 >;                   /* in btr-shields/boards/st/nucleo_f401re_btr/nucleo_f401re_btr.dts:95 */
			status = "okay";                               /* in btr-shields/boards/st/nucleo_f401re_btr/nucleo_f401re_btr.dts:96 */
		};

		/* node '/soc/serial@40004400' defined in zephyr-rigs/dts/arm/st/f4/stm32f4.dtsi:299 */
		usart2: serial@40004400 {
			compatible = "st,stm32-usart",
			             "st,stm32-uart";                  /* in zephyr-rigs/dts/arm/st/f4/stm32f4.dtsi:300 */
			reg = < 0x40004400 0x400 >;                    /* in zephyr-rigs/dts/arm/st/f4/stm32f4.dtsi:301 */
			clocks = < &rcc 0x40 0x20000 >;                /* in zephyr-rigs/dts/arm/st/f4/stm32f4.dtsi:302 */
			resets = < &rctl 0x411 >;                      /* in zephyr-rigs/dts/arm/st/f4/stm32f4.dtsi:303 */
			interrupts = < 0x26 0x0 >;                     /* in zephyr-rigs/dts/arm/st/f4/stm32f4.dtsi:304 */
			pinctrl-0 = < &usart2_tx_pa2 &usart2_rx_pa3 >; /* in btr-shields/boards/st/nucleo_f401re_btr/nucleo_f401re_btr.dts:100 */
			pinctrl-names = "default";                     /* in btr-shields/boards/st/nucleo_f401re_btr/nucleo_f401re_btr.dts:101 */
			current-speed = < 0x1c200 >;                   /* in btr-shields/boards/st/nucleo_f401re_btr/nucleo_f401re_btr.dts:102 */
			status = "okay";                               /* in btr-shields/boards/st/nucleo_f401re_btr/nucleo_f401re_btr.dts:103 */
		};

		/* node '/soc/serial@40011400' defined in zephyr-rigs/dts/arm/st/f4/stm32f4.dtsi:308 */
		usart6: serial@40011400 {
			compatible = "st,stm32-usart",
			             "st,stm32-uart";  /* in zephyr-rigs/dts/arm/st/f4/stm32f4.dtsi:309 */
			reg = < 0x40011400 0x400 >;    /* in zephyr-rigs/dts/arm/st/f4/stm32f4.dtsi:310 */
			clocks = < &rcc 0x44 0x20 >;   /* in zephyr-rigs/dts/arm/st/f4/stm32f4.dtsi:311 */
			resets = < &rctl 0x485 >;      /* in zephyr-rigs/dts/arm/st/f4/stm32f4.dtsi:312 */
			interrupts = < 0x47 0x0 >;     /* in zephyr-rigs/dts/arm/st/f4/stm32f4.dtsi:313 */
			status = "disabled";           /* in zephyr-rigs/dts/arm/st/f4/stm32f4.dtsi:314 */
		};

		/* node '/soc/i2c@40005400' defined in zephyr-rigs/dts/arm/st/f4/stm32f4.dtsi:317 */
		i2c1: i2c@40005400 {
			compatible = "st,stm32-i2c-v1";              /* in zephyr-rigs/dts/arm/st/f4/stm32f4.dtsi:318 */
			#address-cells = < 0x1 >;                    /* in zephyr-rigs/dts/arm/st/f4/stm32f4.dtsi:320 */
			#size-cells = < 0x0 >;                       /* in zephyr-rigs/dts/arm/st/f4/stm32f4.dtsi:321 */
			reg = < 0x40005400 0x400 >;                  /* in zephyr-rigs/dts/arm/st/f4/stm32f4.dtsi:322 */
			clocks = < &rcc 0x40 0x200000 >;             /* in zephyr-rigs/dts/arm/st/f4/stm32f4.dtsi:323 */
			interrupts = < 0x1f 0x0 >,
			             < 0x20 0x0 >;                   /* in zephyr-rigs/dts/arm/st/f4/stm32f4.dtsi:324 */
			interrupt-names = "event",
			                  "error";                   /* in zephyr-rigs/dts/arm/st/f4/stm32f4.dtsi:325 */
			pinctrl-0 = < &i2c1_scl_pb8 &i2c1_sda_pb9 >; /* in btr-shields/boards/st/nucleo_f401re_btr/nucleo_f401re_btr.dts:107 */
			pinctrl-names = "default";                   /* in btr-shields/boards/st/nucleo_f401re_btr/nucleo_f401re_btr.dts:108 */
			scl-gpios = < &gpiob 0x8 0x0 >;              /* in btr-shields/boards/st/nucleo_f401re_btr/nucleo_f401re_btr.dts:109 */
			sda-gpios = < &gpiob 0x9 0x0 >;              /* in btr-shields/boards/st/nucleo_f401re_btr/nucleo_f401re_btr.dts:110 */
			status = "okay";                             /* in btr-shields/boards/st/nucleo_f401re_btr/nucleo_f401re_btr.dts:111 */
			clock-frequency = < 0x61a80 >;               /* in btr-shields/boards/st/nucleo_f401re_btr/nucleo_f401re_btr.dts:112 */
			phandle = < 0x22 >;                          /* in zephyr-rigs/dts/arm/st/f4/stm32f4.dtsi:707 */

			/* node '/soc/i2c@40005400/rtc@68' defined in <RIGEXP_BUILD>/rig/overlay:6 */
			logger_1_dl_rtc: rtc@68 {
				compatible = "nxp,pcf8523";            /* in <RIGEXP_BUILD>/rig/overlay:7 */
				alarms-count = < 0x1 >;                /* in <RIGEXP_BUILD>/rig/overlay:8 */
				battery-switch-over = "standard";      /* in <RIGEXP_BUILD>/rig/overlay:9 */
				reg = < 0x68 >;                        /* in <RIGEXP_BUILD>/rig/overlay:10 */
				int1-gpios = < &nucleo_ard 0xd 0x11 >; /* in <RIGEXP_BUILD>/rig/overlay:11 */
				status = "okay";                       /* in <RIGEXP_BUILD>/rig/overlay:12 */
			};
		};

		/* node '/soc/i2c@40005800' defined in zephyr-rigs/dts/arm/st/f4/stm32f4.dtsi:329 */
		i2c2: i2c@40005800 {
			compatible = "st,stm32-i2c-v1";  /* in zephyr-rigs/dts/arm/st/f4/stm32f4.dtsi:330 */
			clock-frequency = < 0x186a0 >;   /* in zephyr-rigs/dts/arm/st/f4/stm32f4.dtsi:331 */
			#address-cells = < 0x1 >;        /* in zephyr-rigs/dts/arm/st/f4/stm32f4.dtsi:332 */
			#size-cells = < 0x0 >;           /* in zephyr-rigs/dts/arm/st/f4/stm32f4.dtsi:333 */
			reg = < 0x40005800 0x400 >;      /* in zephyr-rigs/dts/arm/st/f4/stm32f4.dtsi:334 */
			clocks = < &rcc 0x40 0x400000 >; /* in zephyr-rigs/dts/arm/st/f4/stm32f4.dtsi:335 */
			interrupts = < 0x21 0x0 >,
			             < 0x22 0x0 >;       /* in zephyr-rigs/dts/arm/st/f4/stm32f4.dtsi:336 */
			interrupt-names = "event",
			                  "error";       /* in zephyr-rigs/dts/arm/st/f4/stm32f4.dtsi:337 */
			status = "disabled";             /* in zephyr-rigs/dts/arm/st/f4/stm32f4.dtsi:338 */
			phandle = < 0x23 >;              /* in zephyr-rigs/dts/arm/st/f4/stm32f4.dtsi:715 */
		};

		/* node '/soc/i2c@40005c00' defined in zephyr-rigs/dts/arm/st/f4/stm32f4.dtsi:341 */
		i2c3: i2c@40005c00 {
			compatible = "st,stm32-i2c-v1";              /* in zephyr-rigs/dts/arm/st/f4/stm32f4.dtsi:342 */
			#address-cells = < 0x1 >;                    /* in zephyr-rigs/dts/arm/st/f4/stm32f4.dtsi:344 */
			#size-cells = < 0x0 >;                       /* in zephyr-rigs/dts/arm/st/f4/stm32f4.dtsi:345 */
			reg = < 0x40005c00 0x400 >;                  /* in zephyr-rigs/dts/arm/st/f4/stm32f4.dtsi:346 */
			clocks = < &rcc 0x40 0x800000 >;             /* in zephyr-rigs/dts/arm/st/f4/stm32f4.dtsi:347 */
			interrupts = < 0x48 0x0 >,
			             < 0x49 0x0 >;                   /* in zephyr-rigs/dts/arm/st/f4/stm32f4.dtsi:348 */
			interrupt-names = "event",
			                  "error";                   /* in zephyr-rigs/dts/arm/st/f4/stm32f4.dtsi:349 */
			pinctrl-0 = < &i2c3_scl_pa8 &i2c3_sda_pc9 >; /* in btr-shields/boards/st/nucleo_f401re_btr/nucleo_f401re_btr.dts:116 */
			pinctrl-names = "default";                   /* in btr-shields/boards/st/nucleo_f401re_btr/nucleo_f401re_btr.dts:117 */
			scl-gpios = < &gpioa 0x8 0x0 >;              /* in btr-shields/boards/st/nucleo_f401re_btr/nucleo_f401re_btr.dts:118 */
			sda-gpios = < &gpioc 0x9 0x0 >;              /* in btr-shields/boards/st/nucleo_f401re_btr/nucleo_f401re_btr.dts:119 */
			status = "okay";                             /* in btr-shields/boards/st/nucleo_f401re_btr/nucleo_f401re_btr.dts:120 */
			clock-frequency = < 0x61a80 >;               /* in btr-shields/boards/st/nucleo_f401re_btr/nucleo_f401re_btr.dts:121 */
			phandle = < 0x24 >;                          /* in zephyr-rigs/dts/arm/st/f4/stm32f4.dtsi:723 */
		};

		/* node '/soc/spi@40013000' defined in zephyr-rigs/dts/arm/st/f4/stm32f4.dtsi:353 */
		spi1: spi@40013000 {
			compatible = "st,stm32-spi";                                 /* in zephyr-rigs/dts/arm/st/f4/stm32f4.dtsi:354 */
			#address-cells = < 0x1 >;                                    /* in zephyr-rigs/dts/arm/st/f4/stm32f4.dtsi:355 */
			#size-cells = < 0x0 >;                                       /* in zephyr-rigs/dts/arm/st/f4/stm32f4.dtsi:356 */
			reg = < 0x40013000 0x400 >;                                  /* in zephyr-rigs/dts/arm/st/f4/stm32f4.dtsi:357 */
			clocks = < &rcc 0x44 0x1000 >;                               /* in zephyr-rigs/dts/arm/st/f4/stm32f4.dtsi:358 */
			interrupts = < 0x23 0x0 >;                                   /* in zephyr-rigs/dts/arm/st/f4/stm32f4.dtsi:359 */
			st,spi-data-width = "limited-8-16-bit";                      /* in zephyr-rigs/dts/arm/st/f4/stm32f4.dtsi:360 */
			pinctrl-0 = < &spi1_sck_pa5 &spi1_miso_pa6 &spi1_mosi_pa7 >; /* in btr-shields/boards/st/nucleo_f401re_btr/nucleo_f401re_btr.dts:125 */
			pinctrl-names = "default";                                   /* in btr-shields/boards/st/nucleo_f401re_btr/nucleo_f401re_btr.dts:126 */
			status = "okay";                                             /* in btr-shields/boards/st/nucleo_f401re_btr/nucleo_f401re_btr.dts:128 */
			cs-gpios = < &nucleo_ard 0x10 0x1 >,
			           < &nucleo_ard 0xf 0x1 >;                          /* in <RIGEXP_BUILD>/rig/overlay:17 */
			phandle = < 0x25 >;                                          /* in btr-shields/boards/st/nucleo_f401re_btr/arduino_r3_socket.dtsi:52 */

			/* node '/soc/spi@40013000/sdhc@0' defined in <RIGEXP_BUILD>/rig/overlay:18 */
			logger_1_dl_sd: sdhc@0 {
				compatible = "zephyr,sdhc-spi-slot"; /* in <RIGEXP_BUILD>/rig/overlay:19 */
				spi-max-frequency = < 0x16e3600 >;   /* in <RIGEXP_BUILD>/rig/overlay:20 */
				reg = < 0x0 >;                       /* in <RIGEXP_BUILD>/rig/overlay:21 */
				status = "okay";                     /* in <RIGEXP_BUILD>/rig/overlay:22 */

				/* node '/soc/spi@40013000/sdhc@0/sdmmc' defined in <RIGEXP_BUILD>/rig/overlay:23 */
				sdmmc {
					compatible = "zephyr,sdmmc-disk"; /* in <RIGEXP_BUILD>/rig/overlay:24 */
					disk-name = "SD";                 /* in <RIGEXP_BUILD>/rig/overlay:25 */
					status = "okay";                  /* in <RIGEXP_BUILD>/rig/overlay:26 */
				};
			};

			/* node '/soc/spi@40013000/wifi@1' defined in <RIGEXP_BUILD>/rig/overlay:29 */
			wifi_1_w_wifi: wifi@1 {
				compatible = "atmel,winc1500";          /* in <RIGEXP_BUILD>/rig/overlay:30 */
				spi-max-frequency = < 0x16e3600 >;      /* in <RIGEXP_BUILD>/rig/overlay:31 */
				reg = < 0x1 >;                          /* in <RIGEXP_BUILD>/rig/overlay:32 */
				irq-gpios = < &nucleo_ard 0x8 0x1 >;    /* in <RIGEXP_BUILD>/rig/overlay:33 */
				reset-gpios = < &nucleo_ard 0xb 0x1 >;  /* in <RIGEXP_BUILD>/rig/overlay:34 */
				enable-gpios = < &nucleo_ard 0xc 0x0 >; /* in <RIGEXP_BUILD>/rig/overlay:35 */
				status = "okay";                        /* in <RIGEXP_BUILD>/rig/overlay:36 */
			};
		};

		/* node '/soc/usb@50000000' defined in zephyr-rigs/dts/arm/st/f4/stm32f4.dtsi:364 */
		usbotg_fs: usb@50000000 {
			compatible = "st,stm32-otgfs"; /* in zephyr-rigs/dts/arm/st/f4/stm32f4.dtsi:365 */
			reg = < 0x50000000 0x40000 >;  /* in zephyr-rigs/dts/arm/st/f4/stm32f4.dtsi:366 */
			interrupts = < 0x43 0x0 >;     /* in zephyr-rigs/dts/arm/st/f4/stm32f4.dtsi:367 */
			interrupt-names = "otgfs";     /* in zephyr-rigs/dts/arm/st/f4/stm32f4.dtsi:368 */
			num-bidir-endpoints = < 0x4 >; /* in zephyr-rigs/dts/arm/st/f4/stm32f4.dtsi:369 */
			ram-size = < 0x500 >;          /* in zephyr-rigs/dts/arm/st/f4/stm32f4.dtsi:370 */
			maximum-speed = "full-speed";  /* in zephyr-rigs/dts/arm/st/f4/stm32f4.dtsi:371 */
			phys = < &otgfs_phy >;         /* in zephyr-rigs/dts/arm/st/f4/stm32f4.dtsi:372 */
			clocks = < &rcc 0x34 0x80 >,
			         < &rcc 0x7 0xff >;    /* in zephyr-rigs/dts/arm/st/f4/stm32f4.dtsi:373 */
			status = "disabled";           /* in zephyr-rigs/dts/arm/st/f4/stm32f4.dtsi:375 */
		};

		/* node '/soc/timers@40010000' defined in zephyr-rigs/dts/arm/st/f4/stm32f4.dtsi:378 */
		timers1: timers@40010000 {
			compatible = "st,stm32-timers"; /* in zephyr-rigs/dts/arm/st/f4/stm32f4.dtsi:379 */
			reg = < 0x40010000 0x400 >;     /* in zephyr-rigs/dts/arm/st/f4/stm32f4.dtsi:380 */
			clocks = < &rcc 0x44 0x1 >,
			         < &rcc 0x16 0xff >;    /* in zephyr-rigs/dts/arm/st/f4/stm32f4.dtsi:381 */
			resets = < &rctl 0x480 >;       /* in zephyr-rigs/dts/arm/st/f4/stm32f4.dtsi:383 */
			interrupts = < 0x18 0x0 >,
			             < 0x19 0x0 >,
			             < 0x1a 0x0 >,
			             < 0x1b 0x0 >;      /* in zephyr-rigs/dts/arm/st/f4/stm32f4.dtsi:384 */
			interrupt-names = "brk",
			                  "up",
			                  "trgcom",
			                  "cc";         /* in zephyr-rigs/dts/arm/st/f4/stm32f4.dtsi:385 */
			st,prescaler = < 0x0 >;         /* in zephyr-rigs/dts/arm/st/f4/stm32f4.dtsi:386 */
			status = "disabled";            /* in zephyr-rigs/dts/arm/st/f4/stm32f4.dtsi:387 */

			/* node '/soc/timers@40010000/pwm' defined in zephyr-rigs/dts/arm/st/f4/stm32f4.dtsi:389 */
			pwm {
				compatible = "st,stm32-pwm"; /* in zephyr-rigs/dts/arm/st/f4/stm32f4.dtsi:390 */
				status = "disabled";         /* in zephyr-rigs/dts/arm/st/f4/stm32f4.dtsi:391 */
				#pwm-cells = < 0x3 >;        /* in zephyr-rigs/dts/arm/st/f4/stm32f4.dtsi:392 */
			};

			/* node '/soc/timers@40010000/counter' defined in zephyr-rigs/dts/arm/st/f4/stm32f4.dtsi:395 */
			counter {
				compatible = "st,stm32-counter"; /* in zephyr-rigs/dts/arm/st/f4/stm32f4.dtsi:396 */
				status = "disabled";             /* in zephyr-rigs/dts/arm/st/f4/stm32f4.dtsi:397 */
			};

			/* node '/soc/timers@40010000/qdec' defined in zephyr-rigs/dts/arm/st/f4/stm32f4.dtsi:400 */
			qdec {
				compatible = "st,stm32-qdec";    /* in zephyr-rigs/dts/arm/st/f4/stm32f4.dtsi:401 */
				st,input-filter-level = < 0x0 >; /* in zephyr-rigs/dts/arm/st/f4/stm32f4.dtsi:402 */
				status = "disabled";             /* in zephyr-rigs/dts/arm/st/f4/stm32f4.dtsi:403 */
			};
		};

		/* node '/soc/timers@40000000' defined in zephyr-rigs/dts/arm/st/f4/stm32f4.dtsi:407 */
		timers2: timers@40000000 {
			compatible = "st,stm32-timers"; /* in zephyr-rigs/dts/arm/st/f4/stm32f4.dtsi:408 */
			reg = < 0x40000000 0x400 >;     /* in zephyr-rigs/dts/arm/st/f4/stm32f4.dtsi:409 */
			clocks = < &rcc 0x40 0x1 >,
			         < &rcc 0x15 0xff >;    /* in zephyr-rigs/dts/arm/st/f4/stm32f4.dtsi:410 */
			resets = < &rctl 0x400 >;       /* in zephyr-rigs/dts/arm/st/f4/stm32f4.dtsi:412 */
			interrupts = < 0x1c 0x0 >;      /* in zephyr-rigs/dts/arm/st/f4/stm32f4.dtsi:413 */
			interrupt-names = "global";     /* in zephyr-rigs/dts/arm/st/f4/stm32f4.dtsi:414 */
			st,prescaler = < 0x0 >;         /* in zephyr-rigs/dts/arm/st/f4/stm32f4.dtsi:415 */
			status = "okay";                /* in btr-shields/boards/st/nucleo_f401re_btr/nucleo_f401re_btr.dts:177 */

			/* node '/soc/timers@40000000/pwm' defined in zephyr-rigs/dts/arm/st/f4/stm32f4.dtsi:418 */
			pwm2: pwm {
				compatible = "st,stm32-pwm";   /* in zephyr-rigs/dts/arm/st/f4/stm32f4.dtsi:419 */
				#pwm-cells = < 0x3 >;          /* in zephyr-rigs/dts/arm/st/f4/stm32f4.dtsi:421 */
				status = "okay";               /* in btr-shields/boards/st/nucleo_f401re_btr/nucleo_f401re_btr.dts:180 */
				pinctrl-0 = < &tim2_ch1_pa5 >; /* in btr-shields/boards/st/nucleo_f401re_btr/nucleo_f401re_btr.dts:181 */
				pinctrl-names = "default";     /* in btr-shields/boards/st/nucleo_f401re_btr/nucleo_f401re_btr.dts:182 */
				phandle = < 0x26 >;            /* in btr-shields/boards/st/nucleo_f401re_btr/nucleo_f401re_btr.dts:39 */
			};

			/* node '/soc/timers@40000000/counter' defined in zephyr-rigs/dts/arm/st/f4/stm32f4.dtsi:424 */
			counter {
				compatible = "st,stm32-counter"; /* in zephyr-rigs/dts/arm/st/f4/stm32f4.dtsi:425 */
				status = "disabled";             /* in zephyr-rigs/dts/arm/st/f4/stm32f4.dtsi:426 */
			};

			/* node '/soc/timers@40000000/qdec' defined in zephyr-rigs/dts/arm/st/f4/stm32f4.dtsi:429 */
			qdec {
				compatible = "st,stm32-qdec";    /* in zephyr-rigs/dts/arm/st/f4/stm32f4.dtsi:430 */
				st,input-filter-level = < 0x0 >; /* in zephyr-rigs/dts/arm/st/f4/stm32f4.dtsi:431 */
				status = "disabled";             /* in zephyr-rigs/dts/arm/st/f4/stm32f4.dtsi:432 */
			};
		};

		/* node '/soc/timers@40000400' defined in zephyr-rigs/dts/arm/st/f4/stm32f4.dtsi:436 */
		timers3: timers@40000400 {
			compatible = "st,stm32-timers"; /* in zephyr-rigs/dts/arm/st/f4/stm32f4.dtsi:437 */
			reg = < 0x40000400 0x400 >;     /* in zephyr-rigs/dts/arm/st/f4/stm32f4.dtsi:438 */
			clocks = < &rcc 0x40 0x2 >,
			         < &rcc 0x15 0xff >;    /* in zephyr-rigs/dts/arm/st/f4/stm32f4.dtsi:439 */
			resets = < &rctl 0x401 >;       /* in zephyr-rigs/dts/arm/st/f4/stm32f4.dtsi:441 */
			interrupts = < 0x1d 0x0 >;      /* in zephyr-rigs/dts/arm/st/f4/stm32f4.dtsi:442 */
			interrupt-names = "global";     /* in zephyr-rigs/dts/arm/st/f4/stm32f4.dtsi:443 */
			st,prescaler = < 0x0 >;         /* in zephyr-rigs/dts/arm/st/f4/stm32f4.dtsi:444 */
			status = "disabled";            /* in zephyr-rigs/dts/arm/st/f4/stm32f4.dtsi:445 */

			/* node '/soc/timers@40000400/pwm' defined in zephyr-rigs/dts/arm/st/f4/stm32f4.dtsi:447 */
			pwm {
				compatible = "st,stm32-pwm"; /* in zephyr-rigs/dts/arm/st/f4/stm32f4.dtsi:448 */
				status = "disabled";         /* in zephyr-rigs/dts/arm/st/f4/stm32f4.dtsi:449 */
				#pwm-cells = < 0x3 >;        /* in zephyr-rigs/dts/arm/st/f4/stm32f4.dtsi:450 */
			};

			/* node '/soc/timers@40000400/counter' defined in zephyr-rigs/dts/arm/st/f4/stm32f4.dtsi:453 */
			counter {
				compatible = "st,stm32-counter"; /* in zephyr-rigs/dts/arm/st/f4/stm32f4.dtsi:454 */
				status = "disabled";             /* in zephyr-rigs/dts/arm/st/f4/stm32f4.dtsi:455 */
			};

			/* node '/soc/timers@40000400/qdec' defined in zephyr-rigs/dts/arm/st/f4/stm32f4.dtsi:458 */
			qdec {
				compatible = "st,stm32-qdec";    /* in zephyr-rigs/dts/arm/st/f4/stm32f4.dtsi:459 */
				st,input-filter-level = < 0x0 >; /* in zephyr-rigs/dts/arm/st/f4/stm32f4.dtsi:460 */
				status = "disabled";             /* in zephyr-rigs/dts/arm/st/f4/stm32f4.dtsi:461 */
			};
		};

		/* node '/soc/timers@40000800' defined in zephyr-rigs/dts/arm/st/f4/stm32f4.dtsi:465 */
		timers4: timers@40000800 {
			compatible = "st,stm32-timers"; /* in zephyr-rigs/dts/arm/st/f4/stm32f4.dtsi:466 */
			reg = < 0x40000800 0x400 >;     /* in zephyr-rigs/dts/arm/st/f4/stm32f4.dtsi:467 */
			clocks = < &rcc 0x40 0x4 >,
			         < &rcc 0x15 0xff >;    /* in zephyr-rigs/dts/arm/st/f4/stm32f4.dtsi:468 */
			resets = < &rctl 0x402 >;       /* in zephyr-rigs/dts/arm/st/f4/stm32f4.dtsi:470 */
			interrupts = < 0x1e 0x0 >;      /* in zephyr-rigs/dts/arm/st/f4/stm32f4.dtsi:471 */
			interrupt-names = "global";     /* in zephyr-rigs/dts/arm/st/f4/stm32f4.dtsi:472 */
			st,prescaler = < 0x0 >;         /* in zephyr-rigs/dts/arm/st/f4/stm32f4.dtsi:473 */
			status = "disabled";            /* in zephyr-rigs/dts/arm/st/f4/stm32f4.dtsi:474 */

			/* node '/soc/timers@40000800/pwm' defined in zephyr-rigs/dts/arm/st/f4/stm32f4.dtsi:476 */
			pwm {
				compatible = "st,stm32-pwm"; /* in zephyr-rigs/dts/arm/st/f4/stm32f4.dtsi:477 */
				status = "disabled";         /* in zephyr-rigs/dts/arm/st/f4/stm32f4.dtsi:478 */
				#pwm-cells = < 0x3 >;        /* in zephyr-rigs/dts/arm/st/f4/stm32f4.dtsi:479 */
			};

			/* node '/soc/timers@40000800/counter' defined in zephyr-rigs/dts/arm/st/f4/stm32f4.dtsi:482 */
			counter {
				compatible = "st,stm32-counter"; /* in zephyr-rigs/dts/arm/st/f4/stm32f4.dtsi:483 */
				status = "disabled";             /* in zephyr-rigs/dts/arm/st/f4/stm32f4.dtsi:484 */
			};

			/* node '/soc/timers@40000800/qdec' defined in zephyr-rigs/dts/arm/st/f4/stm32f4.dtsi:487 */
			qdec {
				compatible = "st,stm32-qdec";    /* in zephyr-rigs/dts/arm/st/f4/stm32f4.dtsi:488 */
				st,input-filter-level = < 0x0 >; /* in zephyr-rigs/dts/arm/st/f4/stm32f4.dtsi:489 */
				status = "disabled";             /* in zephyr-rigs/dts/arm/st/f4/stm32f4.dtsi:490 */
			};
		};

		/* node '/soc/timers@40000c00' defined in zephyr-rigs/dts/arm/st/f4/stm32f4.dtsi:494 */
		timers5: timers@40000c00 {
			compatible = "st,stm32-timers"; /* in zephyr-rigs/dts/arm/st/f4/stm32f4.dtsi:495 */
			reg = < 0x40000c00 0x400 >;     /* in zephyr-rigs/dts/arm/st/f4/stm32f4.dtsi:496 */
			clocks = < &rcc 0x40 0x8 >,
			         < &rcc 0x15 0xff >;    /* in zephyr-rigs/dts/arm/st/f4/stm32f4.dtsi:497 */
			resets = < &rctl 0x403 >;       /* in zephyr-rigs/dts/arm/st/f4/stm32f4.dtsi:499 */
			interrupts = < 0x32 0x0 >;      /* in zephyr-rigs/dts/arm/st/f4/stm32f4.dtsi:500 */
			interrupt-names = "global";     /* in zephyr-rigs/dts/arm/st/f4/stm32f4.dtsi:501 */
			st,prescaler = < 0x0 >;         /* in zephyr-rigs/dts/arm/st/f4/stm32f4.dtsi:502 */
			status = "disabled";            /* in zephyr-rigs/dts/arm/st/f4/stm32f4.dtsi:503 */

			/* node '/soc/timers@40000c00/pwm' defined in zephyr-rigs/dts/arm/st/f4/stm32f4.dtsi:505 */
			pwm {
				compatible = "st,stm32-pwm"; /* in zephyr-rigs/dts/arm/st/f4/stm32f4.dtsi:506 */
				status = "disabled";         /* in zephyr-rigs/dts/arm/st/f4/stm32f4.dtsi:507 */
				#pwm-cells = < 0x3 >;        /* in zephyr-rigs/dts/arm/st/f4/stm32f4.dtsi:508 */
			};

			/* node '/soc/timers@40000c00/counter' defined in zephyr-rigs/dts/arm/st/f4/stm32f4.dtsi:511 */
			counter {
				compatible = "st,stm32-counter"; /* in zephyr-rigs/dts/arm/st/f4/stm32f4.dtsi:512 */
				status = "disabled";             /* in zephyr-rigs/dts/arm/st/f4/stm32f4.dtsi:513 */
			};

			/* node '/soc/timers@40000c00/qdec' defined in zephyr-rigs/dts/arm/st/f4/stm32f4.dtsi:516 */
			qdec {
				compatible = "st,stm32-qdec";    /* in zephyr-rigs/dts/arm/st/f4/stm32f4.dtsi:517 */
				st,input-filter-level = < 0x0 >; /* in zephyr-rigs/dts/arm/st/f4/stm32f4.dtsi:518 */
				status = "disabled";             /* in zephyr-rigs/dts/arm/st/f4/stm32f4.dtsi:519 */
			};
		};

		/* node '/soc/timers@40014000' defined in zephyr-rigs/dts/arm/st/f4/stm32f4.dtsi:523 */
		timers9: timers@40014000 {
			compatible = "st,stm32-timers"; /* in zephyr-rigs/dts/arm/st/f4/stm32f4.dtsi:524 */
			reg = < 0x40014000 0x400 >;     /* in zephyr-rigs/dts/arm/st/f4/stm32f4.dtsi:525 */
			clocks = < &rcc 0x44 0x10000 >,
			         < &rcc 0x16 0xff >;    /* in zephyr-rigs/dts/arm/st/f4/stm32f4.dtsi:526 */
			resets = < &rctl 0x490 >;       /* in zephyr-rigs/dts/arm/st/f4/stm32f4.dtsi:528 */
			interrupts = < 0x18 0x0 >;      /* in zephyr-rigs/dts/arm/st/f4/stm32f4.dtsi:529 */
			interrupt-names = "global";     /* in zephyr-rigs/dts/arm/st/f4/stm32f4.dtsi:530 */
			st,prescaler = < 0x0 >;         /* in zephyr-rigs/dts/arm/st/f4/stm32f4.dtsi:531 */
			status = "disabled";            /* in zephyr-rigs/dts/arm/st/f4/stm32f4.dtsi:532 */

			/* node '/soc/timers@40014000/pwm' defined in zephyr-rigs/dts/arm/st/f4/stm32f4.dtsi:534 */
			pwm {
				compatible = "st,stm32-pwm"; /* in zephyr-rigs/dts/arm/st/f4/stm32f4.dtsi:535 */
				status = "disabled";         /* in zephyr-rigs/dts/arm/st/f4/stm32f4.dtsi:536 */
				#pwm-cells = < 0x3 >;        /* in zephyr-rigs/dts/arm/st/f4/stm32f4.dtsi:537 */
			};

			/* node '/soc/timers@40014000/counter' defined in zephyr-rigs/dts/arm/st/f4/stm32f4.dtsi:540 */
			counter {
				compatible = "st,stm32-counter"; /* in zephyr-rigs/dts/arm/st/f4/stm32f4.dtsi:541 */
				status = "disabled";             /* in zephyr-rigs/dts/arm/st/f4/stm32f4.dtsi:542 */
			};
		};

		/* node '/soc/timers@40014400' defined in zephyr-rigs/dts/arm/st/f4/stm32f4.dtsi:546 */
		timers10: timers@40014400 {
			compatible = "st,stm32-timers"; /* in zephyr-rigs/dts/arm/st/f4/stm32f4.dtsi:547 */
			reg = < 0x40014400 0x400 >;     /* in zephyr-rigs/dts/arm/st/f4/stm32f4.dtsi:548 */
			clocks = < &rcc 0x44 0x20000 >,
			         < &rcc 0x16 0xff >;    /* in zephyr-rigs/dts/arm/st/f4/stm32f4.dtsi:549 */
			resets = < &rctl 0x491 >;       /* in zephyr-rigs/dts/arm/st/f4/stm32f4.dtsi:551 */
			interrupts = < 0x19 0x0 >;      /* in zephyr-rigs/dts/arm/st/f4/stm32f4.dtsi:552 */
			interrupt-names = "global";     /* in zephyr-rigs/dts/arm/st/f4/stm32f4.dtsi:553 */
			st,prescaler = < 0x0 >;         /* in zephyr-rigs/dts/arm/st/f4/stm32f4.dtsi:554 */
			status = "disabled";            /* in zephyr-rigs/dts/arm/st/f4/stm32f4.dtsi:555 */

			/* node '/soc/timers@40014400/pwm' defined in zephyr-rigs/dts/arm/st/f4/stm32f4.dtsi:557 */
			pwm {
				compatible = "st,stm32-pwm"; /* in zephyr-rigs/dts/arm/st/f4/stm32f4.dtsi:558 */
				status = "disabled";         /* in zephyr-rigs/dts/arm/st/f4/stm32f4.dtsi:559 */
				#pwm-cells = < 0x3 >;        /* in zephyr-rigs/dts/arm/st/f4/stm32f4.dtsi:560 */
			};

			/* node '/soc/timers@40014400/counter' defined in zephyr-rigs/dts/arm/st/f4/stm32f4.dtsi:563 */
			counter {
				compatible = "st,stm32-counter"; /* in zephyr-rigs/dts/arm/st/f4/stm32f4.dtsi:564 */
				status = "disabled";             /* in zephyr-rigs/dts/arm/st/f4/stm32f4.dtsi:565 */
			};
		};

		/* node '/soc/timers@40014800' defined in zephyr-rigs/dts/arm/st/f4/stm32f4.dtsi:569 */
		timers11: timers@40014800 {
			compatible = "st,stm32-timers"; /* in zephyr-rigs/dts/arm/st/f4/stm32f4.dtsi:570 */
			reg = < 0x40014800 0x400 >;     /* in zephyr-rigs/dts/arm/st/f4/stm32f4.dtsi:571 */
			clocks = < &rcc 0x44 0x40000 >,
			         < &rcc 0x16 0xff >;    /* in zephyr-rigs/dts/arm/st/f4/stm32f4.dtsi:572 */
			resets = < &rctl 0x492 >;       /* in zephyr-rigs/dts/arm/st/f4/stm32f4.dtsi:574 */
			interrupts = < 0x1a 0x0 >;      /* in zephyr-rigs/dts/arm/st/f4/stm32f4.dtsi:575 */
			interrupt-names = "global";     /* in zephyr-rigs/dts/arm/st/f4/stm32f4.dtsi:576 */
			st,prescaler = < 0x0 >;         /* in zephyr-rigs/dts/arm/st/f4/stm32f4.dtsi:577 */
			status = "disabled";            /* in zephyr-rigs/dts/arm/st/f4/stm32f4.dtsi:578 */

			/* node '/soc/timers@40014800/pwm' defined in zephyr-rigs/dts/arm/st/f4/stm32f4.dtsi:580 */
			pwm {
				compatible = "st,stm32-pwm"; /* in zephyr-rigs/dts/arm/st/f4/stm32f4.dtsi:581 */
				status = "disabled";         /* in zephyr-rigs/dts/arm/st/f4/stm32f4.dtsi:582 */
				#pwm-cells = < 0x3 >;        /* in zephyr-rigs/dts/arm/st/f4/stm32f4.dtsi:583 */
			};

			/* node '/soc/timers@40014800/counter' defined in zephyr-rigs/dts/arm/st/f4/stm32f4.dtsi:586 */
			counter {
				compatible = "st,stm32-counter"; /* in zephyr-rigs/dts/arm/st/f4/stm32f4.dtsi:587 */
				status = "disabled";             /* in zephyr-rigs/dts/arm/st/f4/stm32f4.dtsi:588 */
			};
		};

		/* node '/soc/rtc@40002800' defined in zephyr-rigs/dts/arm/st/f4/stm32f4.dtsi:592 */
		rtc: rtc@40002800 {
			compatible = "st,stm32-rtc";       /* in zephyr-rigs/dts/arm/st/f4/stm32f4.dtsi:593 */
			reg = < 0x40002800 0x400 >;        /* in zephyr-rigs/dts/arm/st/f4/stm32f4.dtsi:594 */
			interrupts = < 0x29 0x0 >;         /* in zephyr-rigs/dts/arm/st/f4/stm32f4.dtsi:595 */
			prescaler = < 0x8000 >;            /* in zephyr-rigs/dts/arm/st/f4/stm32f4.dtsi:597 */
			alarms-count = < 0x2 >;            /* in zephyr-rigs/dts/arm/st/f4/stm32f4.dtsi:598 */
			alrm-exti-line = < 0x11 >;         /* in zephyr-rigs/dts/arm/st/f4/stm32f4.dtsi:599 */
			clocks = < &rcc 0x40 0x10000000 >,
			         < &rcc 0x3 0x2280070 >;   /* in btr-shields/boards/st/nucleo_f401re_btr/nucleo_f401re_btr.dts:187 */
			status = "okay";                   /* in btr-shields/boards/st/nucleo_f401re_btr/nucleo_f401re_btr.dts:189 */

			/* node '/soc/rtc@40002800/backup_regs' defined in zephyr-rigs/dts/arm/st/f4/stm32f4.dtsi:602 */
			bbram: backup_regs {
				compatible = "st,stm32-bbram"; /* in zephyr-rigs/dts/arm/st/f4/stm32f4.dtsi:603 */
				st,backup-regs = < 0x14 >;     /* in zephyr-rigs/dts/arm/st/f4/stm32f4.dtsi:604 */
				status = "disabled";           /* in zephyr-rigs/dts/arm/st/f4/stm32f4.dtsi:605 */
			};
		};

		/* node '/soc/adc@40012000' defined in zephyr-rigs/dts/arm/st/f4/stm32f4.dtsi:609 */
		adc1: adc@40012000 {
			compatible = "st,stm32f4-adc",
			             "st,stm32-adc";                                 /* in zephyr-rigs/dts/arm/st/f4/stm32f4.dtsi:610 */
			reg = < 0x40012000 0x400 >;                                  /* in zephyr-rigs/dts/arm/st/f4/stm32f4.dtsi:611 */
			clocks = < &rcc 0x44 0x100 >;                                /* in zephyr-rigs/dts/arm/st/f4/stm32f4.dtsi:612 */
			clock-names = "adcx";                                        /* in zephyr-rigs/dts/arm/st/f4/stm32f4.dtsi:613 */
			interrupts = < 0x12 0x0 >;                                   /* in zephyr-rigs/dts/arm/st/f4/stm32f4.dtsi:614 */
			#io-channel-cells = < 0x1 >;                                 /* in zephyr-rigs/dts/arm/st/f4/stm32f4.dtsi:615 */
			st,adc-resolutions = < 0xc 0xa 0x8 0x6 >;                    /* in zephyr-rigs/dts/arm/st/f4/stm32f4.dtsi:616 */
			sampling-times = < 0x3 0xf 0x1c 0x38 0x54 0x70 0x90 0x1e0 >; /* in zephyr-rigs/dts/arm/st/f4/stm32f4.dtsi:617 */
			st,adc-sequencer = "programmable";                           /* in zephyr-rigs/dts/arm/st/f4/stm32f4.dtsi:619 */
			st,adc-oversampler = "none";                                 /* in zephyr-rigs/dts/arm/st/f4/stm32f4.dtsi:620 */
			st,adc-internal-regulator = "none";                          /* in zephyr-rigs/dts/arm/st/f4/stm32f4.dtsi:621 */
			st,adc-has-injected-support;                                 /* in zephyr-rigs/dts/arm/st/f4/stm32f4.dtsi:622 */
			pinctrl-0 = < &adc1_in0_pa0 >;                               /* in btr-shields/boards/st/nucleo_f401re_btr/nucleo_f401re_btr.dts:193 */
			pinctrl-names = "default";                                   /* in btr-shields/boards/st/nucleo_f401re_btr/nucleo_f401re_btr.dts:194 */
			st,adc-clock-source = "SYNC";                                /* in btr-shields/boards/st/nucleo_f401re_btr/nucleo_f401re_btr.dts:195 */
			st,adc-prescaler = < 0x2 >;                                  /* in btr-shields/boards/st/nucleo_f401re_btr/nucleo_f401re_btr.dts:196 */
			status = "okay";                                             /* in btr-shields/boards/st/nucleo_f401re_btr/nucleo_f401re_btr.dts:197 */
			phandle = < 0x20 >;                                          /* in zephyr-rigs/dts/arm/st/f4/stm32f4.dtsi:679 */
		};

		/* node '/soc/dma@40026000' defined in zephyr-rigs/dts/arm/st/f4/stm32f4.dtsi:626 */
		dma1: dma@40026000 {
			compatible = "st,stm32-dma-v1";                                                      /* in zephyr-rigs/dts/arm/st/f4/stm32f4.dtsi:627 */
			#dma-cells = < 0x4 >;                                                                /* in zephyr-rigs/dts/arm/st/f4/stm32f4.dtsi:628 */
			reg = < 0x40026000 0x400 >;                                                          /* in zephyr-rigs/dts/arm/st/f4/stm32f4.dtsi:629 */
			interrupts = < 0xb 0x0 0xc 0x0 0xd 0x0 0xe 0x0 0xf 0x0 0x10 0x0 0x11 0x0 0x2f 0x0 >; /* in zephyr-rigs/dts/arm/st/f4/stm32f4.dtsi:630 */
			clocks = < &rcc 0x30 0x200000 >;                                                     /* in zephyr-rigs/dts/arm/st/f4/stm32f4.dtsi:631 */
			status = "disabled";                                                                 /* in zephyr-rigs/dts/arm/st/f4/stm32f4.dtsi:632 */
			phandle = < 0x1b >;                                                                  /* in zephyr-rigs/dts/arm/st/f4/stm32f401.dtsi:61 */
		};

		/* node '/soc/dma@40026400' defined in zephyr-rigs/dts/arm/st/f4/stm32f4.dtsi:635 */
		dma2: dma@40026400 {
			compatible = "st,stm32-dma-v1";                                                           /* in zephyr-rigs/dts/arm/st/f4/stm32f4.dtsi:636 */
			#dma-cells = < 0x4 >;                                                                     /* in zephyr-rigs/dts/arm/st/f4/stm32f4.dtsi:637 */
			reg = < 0x40026400 0x400 >;                                                               /* in zephyr-rigs/dts/arm/st/f4/stm32f4.dtsi:638 */
			interrupts = < 0x38 0x0 0x39 0x0 0x3a 0x0 0x3b 0x0 0x3c 0x0 0x44 0x0 0x45 0x0 0x46 0x0 >; /* in zephyr-rigs/dts/arm/st/f4/stm32f4.dtsi:639 */
			clocks = < &rcc 0x30 0x400000 >;                                                          /* in zephyr-rigs/dts/arm/st/f4/stm32f4.dtsi:640 */
			st,mem2mem;                                                                               /* in zephyr-rigs/dts/arm/st/f4/stm32f4.dtsi:641 */
			status = "disabled";                                                                      /* in zephyr-rigs/dts/arm/st/f4/stm32f4.dtsi:642 */
		};

		/* node '/soc/sdmmc@40012c00' defined in zephyr-rigs/dts/arm/st/f4/stm32f4.dtsi:645 */
		sdmmc1: sdmmc@40012c00 {
			compatible = "st,stm32-sdmmc"; /* in zephyr-rigs/dts/arm/st/f4/stm32f4.dtsi:646 */
			reg = < 0x40012c00 0x400 >;    /* in zephyr-rigs/dts/arm/st/f4/stm32f4.dtsi:647 */
			clocks = < &rcc 0x44 0x800 >,
			         < &rcc 0x7 0xff >;    /* in zephyr-rigs/dts/arm/st/f4/stm32f4.dtsi:648 */
			resets = < &rctl 0x48b >;      /* in zephyr-rigs/dts/arm/st/f4/stm32f4.dtsi:650 */
			interrupts = < 0x31 0x0 >;     /* in zephyr-rigs/dts/arm/st/f4/stm32f4.dtsi:651 */
			status = "disabled";           /* in zephyr-rigs/dts/arm/st/f4/stm32f4.dtsi:652 */
		};

		/* node '/soc/spi@40003800' defined in zephyr-rigs/dts/arm/st/f4/stm32f401.dtsi:21 */
		spi2: spi@40003800 {
			compatible = "st,stm32-spi";                                                   /* in zephyr-rigs/dts/arm/st/f4/stm32f401.dtsi:22 */
			#address-cells = < 0x1 >;                                                      /* in zephyr-rigs/dts/arm/st/f4/stm32f401.dtsi:23 */
			#size-cells = < 0x0 >;                                                         /* in zephyr-rigs/dts/arm/st/f4/stm32f401.dtsi:24 */
			reg = < 0x40003800 0x400 >;                                                    /* in zephyr-rigs/dts/arm/st/f4/stm32f401.dtsi:25 */
			clocks = < &rcc 0x40 0x4000 >;                                                 /* in zephyr-rigs/dts/arm/st/f4/stm32f401.dtsi:26 */
			interrupts = < 0x24 0x0 >;                                                     /* in zephyr-rigs/dts/arm/st/f4/stm32f401.dtsi:27 */
			st,spi-data-width = "limited-8-16-bit";                                        /* in zephyr-rigs/dts/arm/st/f4/stm32f401.dtsi:28 */
			pinctrl-0 = < &spi2_nss_pb12 &spi2_sck_pb13 &spi2_miso_pb14 &spi2_mosi_pb15 >; /* in btr-shields/boards/st/nucleo_f401re_btr/nucleo_f401re_btr.dts:132 */
			pinctrl-names = "default";                                                     /* in btr-shields/boards/st/nucleo_f401re_btr/nucleo_f401re_btr.dts:134 */
			status = "okay";                                                               /* in btr-shields/boards/st/nucleo_f401re_btr/nucleo_f401re_btr.dts:135 */
		};

		/* node '/soc/spi@40003c00' defined in zephyr-rigs/dts/arm/st/f4/stm32f401.dtsi:32 */
		spi3: spi@40003c00 {
			compatible = "st,stm32-spi";            /* in zephyr-rigs/dts/arm/st/f4/stm32f401.dtsi:33 */
			#address-cells = < 0x1 >;               /* in zephyr-rigs/dts/arm/st/f4/stm32f401.dtsi:34 */
			#size-cells = < 0x0 >;                  /* in zephyr-rigs/dts/arm/st/f4/stm32f401.dtsi:35 */
			reg = < 0x40003c00 0x400 >;             /* in zephyr-rigs/dts/arm/st/f4/stm32f401.dtsi:36 */
			clocks = < &rcc 0x40 0x8000 >;          /* in zephyr-rigs/dts/arm/st/f4/stm32f401.dtsi:37 */
			interrupts = < 0x33 0x0 >;              /* in zephyr-rigs/dts/arm/st/f4/stm32f401.dtsi:38 */
			st,spi-data-width = "limited-8-16-bit"; /* in zephyr-rigs/dts/arm/st/f4/stm32f401.dtsi:39 */
			status = "disabled";                    /* in zephyr-rigs/dts/arm/st/f4/stm32f401.dtsi:40 */
		};

		/* node '/soc/spi@40013400' defined in zephyr-rigs/dts/arm/st/f4/stm32f401.dtsi:43 */
		spi4: spi@40013400 {
			compatible = "st,stm32-spi";            /* in zephyr-rigs/dts/arm/st/f4/stm32f401.dtsi:44 */
			#address-cells = < 0x1 >;               /* in zephyr-rigs/dts/arm/st/f4/stm32f401.dtsi:45 */
			#size-cells = < 0x0 >;                  /* in zephyr-rigs/dts/arm/st/f4/stm32f401.dtsi:46 */
			reg = < 0x40013400 0x400 >;             /* in zephyr-rigs/dts/arm/st/f4/stm32f401.dtsi:47 */
			clocks = < &rcc 0x44 0x2000 >;          /* in zephyr-rigs/dts/arm/st/f4/stm32f401.dtsi:48 */
			interrupts = < 0x54 0x0 >;              /* in zephyr-rigs/dts/arm/st/f4/stm32f401.dtsi:49 */
			st,spi-data-width = "limited-8-16-bit"; /* in zephyr-rigs/dts/arm/st/f4/stm32f401.dtsi:50 */
			status = "disabled";                    /* in zephyr-rigs/dts/arm/st/f4/stm32f401.dtsi:51 */
		};

		/* node '/soc/i2s@40003800' defined in zephyr-rigs/dts/arm/st/f4/stm32f401.dtsi:54 */
		i2s2: i2s@40003800 {
			compatible = "st,stm32-i2s";        /* in zephyr-rigs/dts/arm/st/f4/stm32f401.dtsi:55 */
			#address-cells = < 0x1 >;           /* in zephyr-rigs/dts/arm/st/f4/stm32f401.dtsi:56 */
			#size-cells = < 0x0 >;              /* in zephyr-rigs/dts/arm/st/f4/stm32f401.dtsi:57 */
			reg = < 0x40003800 0x400 >;         /* in zephyr-rigs/dts/arm/st/f4/stm32f401.dtsi:58 */
			clocks = < &rcc 0x40 0x4000 >;      /* in zephyr-rigs/dts/arm/st/f4/stm32f401.dtsi:59 */
			interrupts = < 0x24 0x0 >;          /* in zephyr-rigs/dts/arm/st/f4/stm32f401.dtsi:60 */
			dmas = < &dma1 0x4 0x0 0x400 0x3 >,
			       < &dma1 0x3 0x0 0x400 0x3 >; /* in zephyr-rigs/dts/arm/st/f4/stm32f401.dtsi:61 */
			dma-names = "tx",
			            "rx";                   /* in zephyr-rigs/dts/arm/st/f4/stm32f401.dtsi:63 */
			status = "disabled";                /* in zephyr-rigs/dts/arm/st/f4/stm32f401.dtsi:64 */
		};

		/* node '/soc/i2s@40003c00' defined in zephyr-rigs/dts/arm/st/f4/stm32f401.dtsi:67 */
		i2s3: i2s@40003c00 {
			compatible = "st,stm32-i2s";        /* in zephyr-rigs/dts/arm/st/f4/stm32f401.dtsi:68 */
			#address-cells = < 0x1 >;           /* in zephyr-rigs/dts/arm/st/f4/stm32f401.dtsi:69 */
			#size-cells = < 0x0 >;              /* in zephyr-rigs/dts/arm/st/f4/stm32f401.dtsi:70 */
			reg = < 0x40003c00 0x400 >;         /* in zephyr-rigs/dts/arm/st/f4/stm32f401.dtsi:71 */
			clocks = < &rcc 0x40 0x8000 >;      /* in zephyr-rigs/dts/arm/st/f4/stm32f401.dtsi:72 */
			interrupts = < 0x33 0x0 >;          /* in zephyr-rigs/dts/arm/st/f4/stm32f401.dtsi:73 */
			dmas = < &dma1 0x5 0x0 0x400 0x3 >,
			       < &dma1 0x0 0x0 0x400 0x3 >; /* in zephyr-rigs/dts/arm/st/f4/stm32f401.dtsi:74 */
			dma-names = "tx",
			            "rx";                   /* in zephyr-rigs/dts/arm/st/f4/stm32f401.dtsi:76 */
			status = "disabled";                /* in zephyr-rigs/dts/arm/st/f4/stm32f401.dtsi:77 */
		};
	};

	/* node '/cpus' defined in zephyr-rigs/dts/arm/st/f4/stm32f4.dtsi:30 */
	cpus {
		#address-cells = < 0x1 >; /* in zephyr-rigs/dts/arm/st/f4/stm32f4.dtsi:31 */
		#size-cells = < 0x0 >;    /* in zephyr-rigs/dts/arm/st/f4/stm32f4.dtsi:32 */

		/* node '/cpus/cpu@0' defined in zephyr-rigs/dts/arm/st/f4/stm32f4.dtsi:34 */
		cpu0: cpu@0 {
			device_type = "cpu";           /* in zephyr-rigs/dts/arm/st/f4/stm32f4.dtsi:35 */
			compatible = "arm,cortex-m4f"; /* in zephyr-rigs/dts/arm/st/f4/stm32f4.dtsi:36 */
			reg = < 0x0 >;                 /* in zephyr-rigs/dts/arm/st/f4/stm32f4.dtsi:37 */
			cpu-power-states = < &stop >;  /* in zephyr-rigs/dts/arm/st/f4/stm32f4.dtsi:38 */
		};

		/* node '/cpus/power-states' defined in zephyr-rigs/dts/arm/st/f4/stm32f4.dtsi:41 */
		power-states {

			/* node '/cpus/power-states/stop' defined in zephyr-rigs/dts/arm/st/f4/stm32f4.dtsi:42 */
			stop: stop {
				compatible = "zephyr,power-state";    /* in zephyr-rigs/dts/arm/st/f4/stm32f4.dtsi:43 */
				power-state-name = "suspend-to-idle"; /* in zephyr-rigs/dts/arm/st/f4/stm32f4.dtsi:44 */
				min-residency-us = < 0x190 >;         /* in zephyr-rigs/dts/arm/st/f4/stm32f4.dtsi:51 */
				exit-latency-us = < 0x12c >;          /* in zephyr-rigs/dts/arm/st/f4/stm32f4.dtsi:52 */
				phandle = < 0x1c >;                   /* in zephyr-rigs/dts/arm/st/f4/stm32f4.dtsi:38 */
			};
		};
	};

	/* node '/memory@20000000' defined in zephyr-rigs/dts/arm/st/f4/stm32f4.dtsi:57 */
	sram0: memory@20000000 {
		compatible = "zephyr,memory-region",
		             "mmio-sram";            /* in zephyr-rigs/dts/arm/st/f4/stm32f4.dtsi:58 */
		zephyr,memory-region = "SRAM0";      /* in zephyr-rigs/dts/arm/st/f4/stm32f4.dtsi:59 */
		reg = < 0x20000000 0x18000 >;        /* in zephyr-rigs/dts/arm/st/f4/stm32f401Xe.dtsi:11 */
	};

	/* node '/clocks' defined in zephyr-rigs/dts/arm/st/f4/stm32f4.dtsi:62 */
	clocks {

		/* node '/clocks/clk-hse' defined in zephyr-rigs/dts/arm/st/f4/stm32f4.dtsi:63 */
		clk_hse: clk-hse {
			#clock-cells = < 0x0 >;            /* in zephyr-rigs/dts/arm/st/f4/stm32f4.dtsi:64 */
			compatible = "st,stm32-hse-clock"; /* in zephyr-rigs/dts/arm/st/f4/stm32f4.dtsi:65 */
			hse-bypass;                        /* in btr-shields/boards/st/nucleo_f401re_btr/nucleo_f401re_btr.dts:70 */
			clock-frequency = < 0x7a1200 >;    /* in btr-shields/boards/st/nucleo_f401re_btr/nucleo_f401re_btr.dts:71 */
			status = "okay";                   /* in btr-shields/boards/st/nucleo_f401re_btr/nucleo_f401re_btr.dts:72 */
			phandle = < 0x1d >;                /* in btr-shields/boards/st/nucleo_f401re_btr/nucleo_f401re_btr.dts:80 */
		};

		/* node '/clocks/clk-hsi' defined in zephyr-rigs/dts/arm/st/f4/stm32f4.dtsi:69 */
		clk_hsi: clk-hsi {
			#clock-cells = < 0x0 >;         /* in zephyr-rigs/dts/arm/st/f4/stm32f4.dtsi:70 */
			compatible = "fixed-clock";     /* in zephyr-rigs/dts/arm/st/f4/stm32f4.dtsi:71 */
			clock-frequency = < 0xf42400 >; /* in zephyr-rigs/dts/arm/st/f4/stm32f4.dtsi:72 */
			status = "disabled";            /* in zephyr-rigs/dts/arm/st/f4/stm32f4.dtsi:73 */
		};

		/* node '/clocks/clk-lse' defined in zephyr-rigs/dts/arm/st/f4/stm32f4.dtsi:76 */
		clk_lse: clk-lse {
			#clock-cells = < 0x0 >;       /* in zephyr-rigs/dts/arm/st/f4/stm32f4.dtsi:77 */
			compatible = "fixed-clock";   /* in zephyr-rigs/dts/arm/st/f4/stm32f4.dtsi:78 */
			clock-frequency = < 0x8000 >; /* in zephyr-rigs/dts/arm/st/f4/stm32f4.dtsi:79 */
			status = "disabled";          /* in zephyr-rigs/dts/arm/st/f4/stm32f4.dtsi:80 */
		};

		/* node '/clocks/clk-lsi' defined in zephyr-rigs/dts/arm/st/f4/stm32f4.dtsi:83 */
		clk_lsi: clk-lsi {
			#clock-cells = < 0x0 >;       /* in zephyr-rigs/dts/arm/st/f4/stm32f4.dtsi:84 */
			compatible = "fixed-clock";   /* in zephyr-rigs/dts/arm/st/f4/stm32f4.dtsi:85 */
			clock-frequency = < 0x7d00 >; /* in zephyr-rigs/dts/arm/st/f4/stm32f4.dtsi:86 */
			status = "okay";              /* in btr-shields/boards/st/nucleo_f401re_btr/nucleo_f401re_btr.dts:66 */
		};

		/* node '/clocks/pll' defined in zephyr-rigs/dts/arm/st/f4/stm32f4.dtsi:90 */
		pll: pll {
			#clock-cells = < 0x0 >;              /* in zephyr-rigs/dts/arm/st/f4/stm32f4.dtsi:91 */
			compatible = "st,stm32fx-pll-clock"; /* in zephyr-rigs/dts/arm/st/f4/stm32f4.dtsi:92 */
			div-m = < 0x8 >;                     /* in btr-shields/boards/st/nucleo_f401re_btr/nucleo_f401re_btr.dts:76 */
			mul-n = < 0x150 >;                   /* in btr-shields/boards/st/nucleo_f401re_btr/nucleo_f401re_btr.dts:77 */
			div-p = < 0x4 >;                     /* in btr-shields/boards/st/nucleo_f401re_btr/nucleo_f401re_btr.dts:78 */
			div-q = < 0x7 >;                     /* in btr-shields/boards/st/nucleo_f401re_btr/nucleo_f401re_btr.dts:79 */
			clocks = < &clk_hse >;               /* in btr-shields/boards/st/nucleo_f401re_btr/nucleo_f401re_btr.dts:80 */
			status = "okay";                     /* in btr-shields/boards/st/nucleo_f401re_btr/nucleo_f401re_btr.dts:81 */
			phandle = < 0x2 >;                   /* in btr-shields/boards/st/nucleo_f401re_btr/nucleo_f401re_btr.dts:85 */
		};

		/* node '/clocks/plli2s' defined in zephyr-rigs/dts/arm/st/f4/stm32f401.dtsi:11 */
		plli2s: plli2s {
			#clock-cells = < 0x0 >;              /* in zephyr-rigs/dts/arm/st/f4/stm32f401.dtsi:12 */
			compatible = "st,stm32fx-pll-clock"; /* in zephyr-rigs/dts/arm/st/f4/stm32f401.dtsi:13 */
			status = "disabled";                 /* in zephyr-rigs/dts/arm/st/f4/stm32f401.dtsi:14 */
		};
	};

	/* node '/mcos' defined in zephyr-rigs/dts/arm/st/f4/stm32f4.dtsi:97 */
	mcos {

		/* node '/mcos/mco1' defined in zephyr-rigs/dts/arm/st/f4/stm32f4.dtsi:98 */
		mco1: mco1 {
			compatible = "st,stm32-clock-mco"; /* in zephyr-rigs/dts/arm/st/f4/stm32f4.dtsi:99 */
			clock-names = "clksel";            /* in zephyr-rigs/dts/arm/st/f4/stm32f4.dtsi:100 */
			status = "disabled";               /* in zephyr-rigs/dts/arm/st/f4/stm32f4.dtsi:101 */
		};

		/* node '/mcos/mco2' defined in zephyr-rigs/dts/arm/st/f4/stm32f4.dtsi:104 */
		mco2: mco2 {
			compatible = "st,stm32-clock-mco"; /* in zephyr-rigs/dts/arm/st/f4/stm32f4.dtsi:105 */
			clock-names = "clksel";            /* in zephyr-rigs/dts/arm/st/f4/stm32f4.dtsi:106 */
			status = "disabled";               /* in zephyr-rigs/dts/arm/st/f4/stm32f4.dtsi:107 */
		};
	};

	/* node '/power@40007000' defined in zephyr-rigs/dts/arm/st/f4/stm32f4.dtsi:656 */
	pwr: power@40007000 {
		compatible = "st,stm32-pwr"; /* in zephyr-rigs/dts/arm/st/f4/stm32f4.dtsi:657 */
		reg = < 0x40007000 0x400 >;  /* in zephyr-rigs/dts/arm/st/f4/stm32f4.dtsi:658 */
		status = "disabled";         /* in zephyr-rigs/dts/arm/st/f4/stm32f4.dtsi:659 */
		wkup-pins-nb = < 0x1 >;      /* in zephyr-rigs/dts/arm/st/f4/stm32f4.dtsi:661 */
		#address-cells = < 0x1 >;    /* in zephyr-rigs/dts/arm/st/f4/stm32f4.dtsi:663 */
		#size-cells = < 0x0 >;       /* in zephyr-rigs/dts/arm/st/f4/stm32f4.dtsi:664 */

		/* node '/power@40007000/wkup-pin@1' defined in zephyr-rigs/dts/arm/st/f4/stm32f4.dtsi:666 */
		wkup-pin@1 {
			reg = < 0x1 >;                   /* in zephyr-rigs/dts/arm/st/f4/stm32f4.dtsi:667 */
			wkup-gpios = < &gpioa 0x0 0x1 >; /* in zephyr-rigs/dts/arm/st/f4/stm32f4.dtsi:668 */
		};
	};

	/* node '/dietemp' defined in zephyr-rigs/dts/arm/st/f4/stm32f4.dtsi:672 */
	die_temp: dietemp {
		compatible = "st,stm32-temp-cal"; /* in zephyr-rigs/dts/arm/st/f4/stm32f4.dtsi:673 */
		nvmem-cells = < &ts_cal1_otp >,
		              < &ts_cal2_otp >;   /* in zephyr-rigs/dts/arm/st/f4/stm32f4.dtsi:674 */
		nvmem-cell-names = "TS_CAL1",
		                   "TS_CAL2";     /* in zephyr-rigs/dts/arm/st/f4/stm32f4.dtsi:675 */
		ts-cal1-temp = < 0x1e >;          /* in zephyr-rigs/dts/arm/st/f4/stm32f4.dtsi:676 */
		ts-cal2-temp = < 0x6e >;          /* in zephyr-rigs/dts/arm/st/f4/stm32f4.dtsi:677 */
		ts-cal-vrefanalog = < 0xce4 >;    /* in zephyr-rigs/dts/arm/st/f4/stm32f4.dtsi:678 */
		io-channels = < &adc1 0x10 >;     /* in zephyr-rigs/dts/arm/st/f4/stm32f4.dtsi:679 */
		status = "okay";                  /* in btr-shields/boards/st/nucleo_f401re_btr/nucleo_f401re_btr.dts:201 */
	};

	/* node '/vref' defined in zephyr-rigs/dts/arm/st/f4/stm32f4.dtsi:683 */
	vref: vref {
		compatible = "st,stm32-vref";   /* in zephyr-rigs/dts/arm/st/f4/stm32f4.dtsi:684 */
		nvmem-cells = < &vrefint_otp >; /* in zephyr-rigs/dts/arm/st/f4/stm32f4.dtsi:685 */
		vrefint-cal-mv = < 0xce4 >;     /* in zephyr-rigs/dts/arm/st/f4/stm32f4.dtsi:686 */
		io-channels = < &adc1 0x11 >;   /* in zephyr-rigs/dts/arm/st/f4/stm32f4.dtsi:687 */
		status = "okay";                /* in btr-shields/boards/st/nucleo_f401re_btr/nucleo_f401re_btr.dts:209 */
	};

	/* node '/vbat' defined in zephyr-rigs/dts/arm/st/f4/stm32f4.dtsi:691 */
	vbat: vbat {
		compatible = "st,stm32-vbat"; /* in zephyr-rigs/dts/arm/st/f4/stm32f4.dtsi:692 */
		ratio = < 0x4 >;              /* in zephyr-rigs/dts/arm/st/f4/stm32f4.dtsi:693 */
		io-channels = < &adc1 0x12 >; /* in zephyr-rigs/dts/arm/st/f4/stm32f4.dtsi:694 */
		status = "okay";              /* in btr-shields/boards/st/nucleo_f401re_btr/nucleo_f401re_btr.dts:213 */
	};

	/* node '/otgfs_phy' defined in zephyr-rigs/dts/arm/st/f4/stm32f4.dtsi:698 */
	otgfs_phy: otgfs_phy {
		compatible = "usb-nop-xceiv"; /* in zephyr-rigs/dts/arm/st/f4/stm32f4.dtsi:699 */
		#phy-cells = < 0x0 >;         /* in zephyr-rigs/dts/arm/st/f4/stm32f4.dtsi:700 */
		phandle = < 0x14 >;           /* in zephyr-rigs/dts/arm/st/f4/stm32f4.dtsi:372 */
	};

	/* node '/smbus1' defined in zephyr-rigs/dts/arm/st/f4/stm32f4.dtsi:703 */
	smbus1: smbus1 {
		compatible = "st,stm32-smbus"; /* in zephyr-rigs/dts/arm/st/f4/stm32f4.dtsi:704 */
		#address-cells = < 0x1 >;      /* in zephyr-rigs/dts/arm/st/f4/stm32f4.dtsi:705 */
		#size-cells = < 0x0 >;         /* in zephyr-rigs/dts/arm/st/f4/stm32f4.dtsi:706 */
		i2c = < &i2c1 >;               /* in zephyr-rigs/dts/arm/st/f4/stm32f4.dtsi:707 */
		status = "disabled";           /* in zephyr-rigs/dts/arm/st/f4/stm32f4.dtsi:708 */
	};

	/* node '/smbus2' defined in zephyr-rigs/dts/arm/st/f4/stm32f4.dtsi:711 */
	smbus2: smbus2 {
		compatible = "st,stm32-smbus"; /* in zephyr-rigs/dts/arm/st/f4/stm32f4.dtsi:712 */
		#address-cells = < 0x1 >;      /* in zephyr-rigs/dts/arm/st/f4/stm32f4.dtsi:713 */
		#size-cells = < 0x0 >;         /* in zephyr-rigs/dts/arm/st/f4/stm32f4.dtsi:714 */
		i2c = < &i2c2 >;               /* in zephyr-rigs/dts/arm/st/f4/stm32f4.dtsi:715 */
		status = "disabled";           /* in zephyr-rigs/dts/arm/st/f4/stm32f4.dtsi:716 */
	};

	/* node '/smbus3' defined in zephyr-rigs/dts/arm/st/f4/stm32f4.dtsi:719 */
	smbus3: smbus3 {
		compatible = "st,stm32-smbus"; /* in zephyr-rigs/dts/arm/st/f4/stm32f4.dtsi:720 */
		#address-cells = < 0x1 >;      /* in zephyr-rigs/dts/arm/st/f4/stm32f4.dtsi:721 */
		#size-cells = < 0x0 >;         /* in zephyr-rigs/dts/arm/st/f4/stm32f4.dtsi:722 */
		i2c = < &i2c3 >;               /* in zephyr-rigs/dts/arm/st/f4/stm32f4.dtsi:723 */
		status = "disabled";           /* in zephyr-rigs/dts/arm/st/f4/stm32f4.dtsi:724 */
	};

	/* node '/connector_arduino_r3' defined in btr-shields/boards/st/nucleo_f401re_btr/arduino_r3_socket.dtsi:24 */
	nucleo_ard: connector_arduino_r3 {
		compatible = "socket,arduino-r3";          /* in btr-shields/boards/st/nucleo_f401re_btr/arduino_r3_socket.dtsi:25 */
		#gpio-cells = < 0x2 >;                     /* in btr-shields/boards/st/nucleo_f401re_btr/arduino_r3_socket.dtsi:26 */
		gpio-map-mask = < 0xffffffff 0xffffffc0 >; /* in btr-shields/boards/st/nucleo_f401re_btr/arduino_r3_socket.dtsi:27 */
		gpio-map-pass-thru = < 0x0 0x3f >;         /* in btr-shields/boards/st/nucleo_f401re_btr/arduino_r3_socket.dtsi:28 */
		gpio-map = < 0x0 0x0 &gpioa 0x0 0x0 >,
		           < 0x1 0x0 &gpioa 0x1 0x0 >,
		           < 0x2 0x0 &gpioa 0x4 0x0 >,
		           < 0x3 0x0 &gpiob 0x0 0x0 >,
		           < 0x4 0x0 &gpioc 0x1 0x0 >,
		           < 0x5 0x0 &gpioc 0x0 0x0 >,
		           < 0x6 0x0 &gpioa 0x3 0x0 >,
		           < 0x7 0x0 &gpioa 0x2 0x0 >,
		           < 0x8 0x0 &gpioa 0xa 0x0 >,
		           < 0x9 0x0 &gpiob 0x3 0x0 >,
		           < 0xa 0x0 &gpiob 0x5 0x0 >,
		           < 0xb 0x0 &gpiob 0x4 0x0 >,
		           < 0xc 0x0 &gpiob 0xa 0x0 >,
		           < 0xd 0x0 &gpioa 0x8 0x0 >,
		           < 0xe 0x0 &gpioa 0x9 0x0 >,
		           < 0xf 0x0 &gpioc 0x7 0x0 >,
		           < 0x10 0x0 &gpiob 0x6 0x0 >,
		           < 0x11 0x0 &gpioa 0x7 0x0 >,
		           < 0x12 0x0 &gpioa 0x6 0x0 >,
		           < 0x13 0x0 &gpioa 0x5 0x0 >,
		           < 0x14 0x0 &gpiob 0x9 0x0 >,
		           < 0x15 0x0 &gpiob 0x8 0x0 >;    /* in btr-shields/boards/st/nucleo_f401re_btr/arduino_r3_socket.dtsi:29 */
		socket,i2c = < &i2c1 >;                    /* in btr-shields/boards/st/nucleo_f401re_btr/arduino_r3_socket.dtsi:51 */
		socket,spi = < &spi1 >;                    /* in btr-shields/boards/st/nucleo_f401re_btr/arduino_r3_socket.dtsi:52 */
		socket,stackable;                          /* in btr-shields/boards/st/nucleo_f401re_btr/arduino_r3_socket.dtsi:53 */
		phandle = < 0xc >;                         /* in <RIGEXP_BUILD>/rig/overlay:11 */
	};

	/* node '/leds' defined in btr-shields/boards/st/nucleo_f401re_btr/nucleo_f401re_btr.dts:26 */
	leds: leds {
		compatible = "gpio-leds"; /* in btr-shields/boards/st/nucleo_f401re_btr/nucleo_f401re_btr.dts:27 */

		/* node '/leds/led_2' defined in btr-shields/boards/st/nucleo_f401re_btr/nucleo_f401re_btr.dts:29 */
		green_led_2: led_2 {
			gpios = < &gpioa 0x5 0x0 >; /* in btr-shields/boards/st/nucleo_f401re_btr/nucleo_f401re_btr.dts:30 */
			label = "User LD2";         /* in btr-shields/boards/st/nucleo_f401re_btr/nucleo_f401re_btr.dts:31 */
		};
	};

	/* node '/pwmleds' defined in btr-shields/boards/st/nucleo_f401re_btr/nucleo_f401re_btr.dts:35 */
	pwmleds {
		compatible = "pwm-leds"; /* in btr-shields/boards/st/nucleo_f401re_btr/nucleo_f401re_btr.dts:36 */

		/* node '/pwmleds/green_pwm_led' defined in btr-shields/boards/st/nucleo_f401re_btr/nucleo_f401re_btr.dts:38 */
		green_pwm_led: green_pwm_led {
			pwms = < &pwm2 0x1 0x1312d00 0x0 >; /* in btr-shields/boards/st/nucleo_f401re_btr/nucleo_f401re_btr.dts:39 */
		};
	};

	/* node '/gpio_keys' defined in btr-shields/boards/st/nucleo_f401re_btr/nucleo_f401re_btr.dts:43 */
	gpio_keys {
		compatible = "gpio-keys"; /* in btr-shields/boards/st/nucleo_f401re_btr/nucleo_f401re_btr.dts:44 */

		/* node '/gpio_keys/button' defined in btr-shields/boards/st/nucleo_f401re_btr/nucleo_f401re_btr.dts:46 */
		user_button: button {
			label = "User";             /* in btr-shields/boards/st/nucleo_f401re_btr/nucleo_f401re_btr.dts:47 */
			gpios = < &gpioc 0xd 0x1 >; /* in btr-shields/boards/st/nucleo_f401re_btr/nucleo_f401re_btr.dts:48 */
			zephyr,code = < 0xb >;      /* in btr-shields/boards/st/nucleo_f401re_btr/nucleo_f401re_btr.dts:49 */
		};
	};

	/* node '/gpio_leds' defined in <RIGEXP_BUILD>/rig/overlay:41 */
	gpio_leds: gpio_leds {
		compatible = "gpio-leds"; /* in <RIGEXP_BUILD>/rig/overlay:42 */

		/* node '/gpio_leds/logger_1_dl_led1' defined in <RIGEXP_BUILD>/rig/overlay:43 */
		logger_1_dl_led1: logger_1_dl_led1 {
			label = "logger_1_dl_led1";      /* in <RIGEXP_BUILD>/rig/overlay:44 */
			gpios = < &nucleo_ard 0x9 0x0 >; /* in <RIGEXP_BUILD>/rig/overlay:45 */
		};

		/* node '/gpio_leds/logger_1_dl_led2' defined in <RIGEXP_BUILD>/rig/overlay:47 */
		logger_1_dl_led2: logger_1_dl_led2 {
			label = "logger_1_dl_led2";      /* in <RIGEXP_BUILD>/rig/overlay:48 */
			gpios = < &nucleo_ard 0xa 0x0 >; /* in <RIGEXP_BUILD>/rig/overlay:49 */
		};
	};
};
